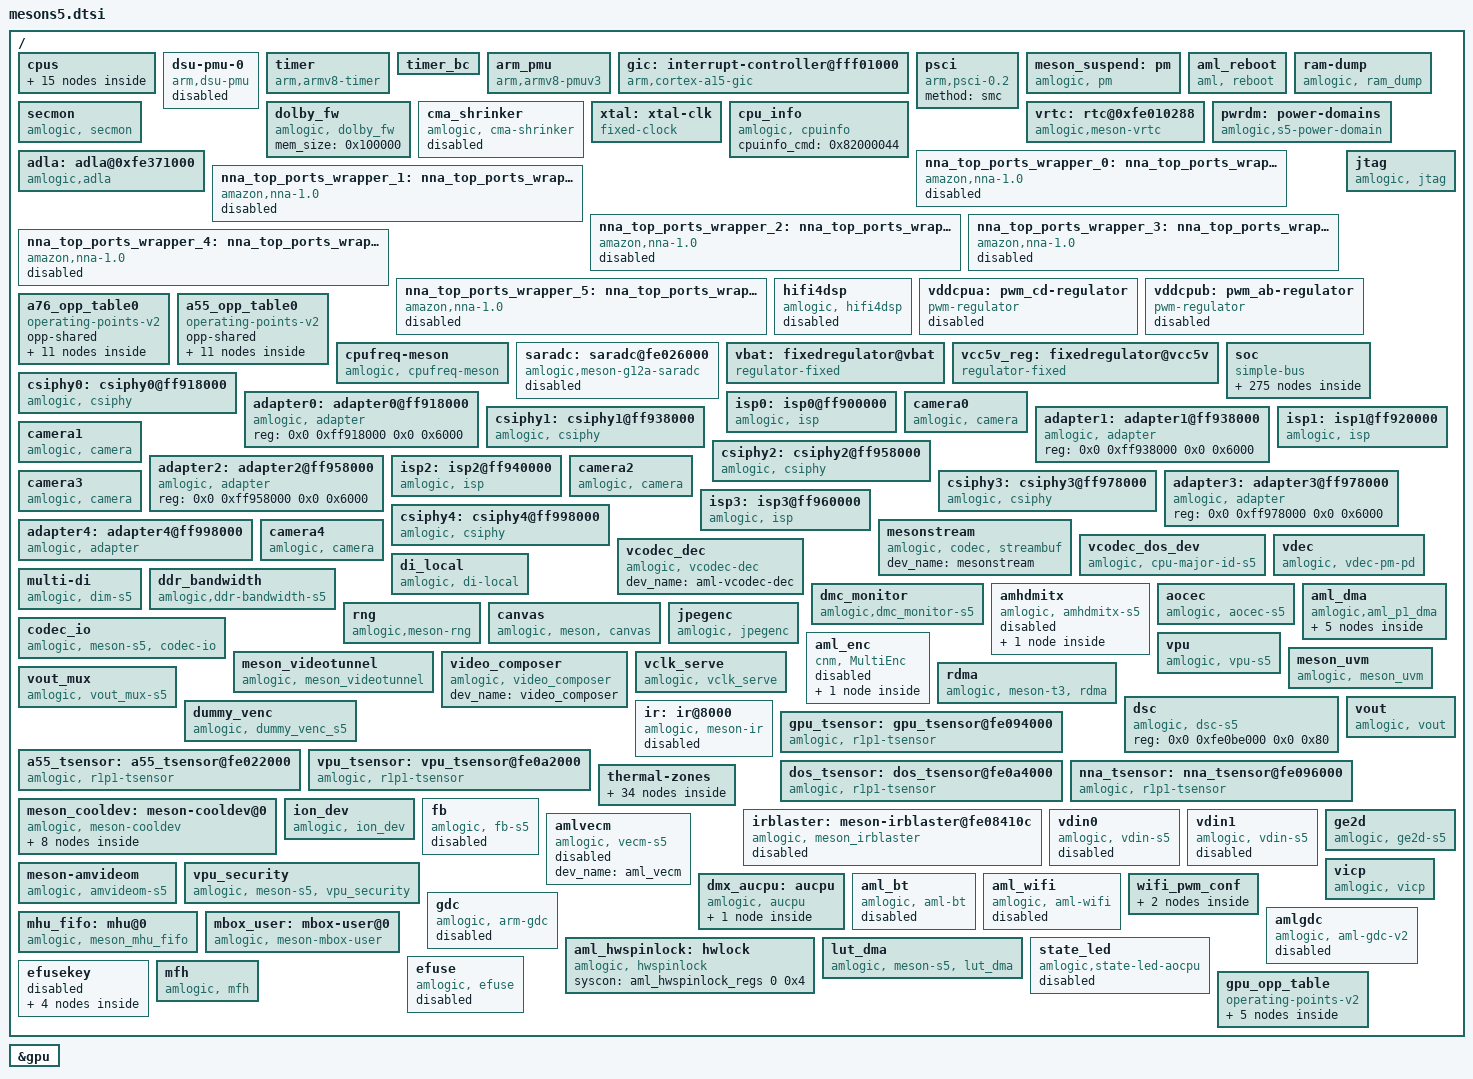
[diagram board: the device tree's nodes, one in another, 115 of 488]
// SPDX-License-Identifier: (GPL-2.0+ OR MIT)
/*
 * Copyright (c) 2019 Amlogic, Inc. All rights reserved.
 */

#include <dt-bindings/clock/s5-clkc.h>
#include <dt-bindings/interrupt-controller/irq.h>
#include <dt-bindings/interrupt-controller/arm-gic.h>
#include <dt-bindings/power/s5-pd.h>
#include <dt-bindings/clock/amlogic,s5-audio-clk.h>
#include <dt-bindings/gpio/gpio.h>
#include <dt-bindings/gpio/meson-s5-gpio.h>
#include <dt-bindings/reset/amlogic,meson-s5-reset.h>
#include <dt-bindings/pwm/pwm.h>
#include <dt-bindings/pwm/meson.h>
#include <dt-bindings/input/input.h>
#include <dt-bindings/input/meson_ir.h>
#include <dt-bindings/mailbox/amlogic,mbox.h>
#include "meson-ir-map.dtsi"
#include "meson-valhall.dtsi"
#include <dt-bindings/memory/meson-p1-sid-map.h>
#include <dt-bindings/hwspinlock/amlogic,hwspinlock.h>
/ {
	cpus:cpus {
		#address-cells = <2>;
		#size-cells = <0>;

		cpu-map {
			cluster0:cluster0 {
				core0 {
					cpu = <&CPU0>;
				};
				core1 {
					cpu = <&CPU1>;
				};
				core2 {
					cpu = <&CPU2>;
				};
				core3 {
					cpu = <&CPU3>;
				};
				core4 {
					cpu = <&CPU4>;
				};
			};
		};

		CPU0:cpu@0 {
			device_type = "cpu";
			compatible = "arm,cortex-a55","arm,armv8";
			reg = <0x0 0x0>;
			enable-method = "psci";
			cpu-idle-states = <&CPU_SLEEP_0 &SYSTEM_SLEEP_0>;
			#cooling-cells = <2>;
			clocks = <&clkc CLKID_CPU_CLK>,
				<&clkc CLKID_CPU_DYN_CLK>,
				<&clkc CLKID_SYS_PLL>,
				<&clkc CLKID_DSU_CLK>,
				<&clkc CLKID_DSU_DYN_CLK>,
				<&clkc CLKID_GP1_PLL>;
			clock-names = "core_clk",
				"low_freq_clk_parent",
				"high_freq_clk_parent",
				"dsu_clk",
				"dsu_pre_parent",
				"dsu_pre_parent2";
			operating-points-v2 = <&a55_opp_table0>;
			voltage-tolerance = <0>;
			clock-latency = <50000>;
			capacity-dmips-mhz = <512>;
			dynamic-power-coefficient = <1024>;
			cpu-supply = <&vddcpua>;
			cpu_supply_external_used;
			dsu-opp-table = <1200000 879000 1500000 939000>;
			dsu_clock_shared;
			dsu-low-rate = <1000000>;
			dvfs_sibling_core_num = <4>;
			dvfs_sibling_cores = <0 1 2 3>;
		};

		CPU1:cpu@1 {
			device_type = "cpu";
			compatible = "arm,cortex-a55","arm,armv8";
			reg = <0x0 0x1>;
			enable-method = "psci";
		    cpu-idle-states = <&CPU_SLEEP_0 &SYSTEM_SLEEP_0>;
			#cooling-cells = <2>;
			clocks = <&clkc CLKID_CPU_CLK>,
				<&clkc CLKID_CPU_DYN_CLK>,
				<&clkc CLKID_SYS_PLL>,
				<&clkc CLKID_DSU_CLK>,
				<&clkc CLKID_DSU_DYN_CLK>,
				<&clkc CLKID_GP1_PLL>;
			clock-names = "core_clk",
				"low_freq_clk_parent",
				"high_freq_clk_parent",
				"dsu_clk",
				"dsu_pre_parent",
				"dsu_pre_parent2";
			operating-points-v2 = <&a55_opp_table0>;
			voltage-tolerance = <0>;
			clock-latency = <50000>;
			capacity-dmips-mhz = <512>;
			dynamic-power-coefficient = <1024>;
			cpu-supply = <&vddcpua>;
			cpu_supply_external_used;
			dsu-opp-table = <1200000 879000 1500000 939000>;
			dsu_clock_shared;
			dsu-low-rate = <1000000>;
			dvfs_sibling_core_num = <4>;
			dvfs_sibling_cores = <0 1 2 3>;
		};

		CPU2:cpu@2 {
			device_type = "cpu";
			compatible = "arm,cortex-a55","arm,armv8";
			reg = <0x0 0x2>;
			enable-method = "psci";
			cpu-idle-states = <&CPU_SLEEP_0 &SYSTEM_SLEEP_0>;
			#cooling-cells = <2>;
			clocks = <&clkc CLKID_CPU_CLK>,
				<&clkc CLKID_CPU_DYN_CLK>,
				<&clkc CLKID_SYS_PLL>,
				<&clkc CLKID_DSU_CLK>,
				<&clkc CLKID_DSU_DYN_CLK>,
				<&clkc CLKID_GP1_PLL>;
			clock-names = "core_clk",
				"low_freq_clk_parent",
				"high_freq_clk_parent",
				"dsu_clk",
				"dsu_pre_parent",
				"dsu_pre_parent2";
			operating-points-v2 = <&a55_opp_table0>;
			voltage-tolerance = <0>;
			clock-latency = <50000>;
			capacity-dmips-mhz = <512>;
			dynamic-power-coefficient = <1024>;
			cpu-supply = <&vddcpua>;
			cpu_supply_external_used;
			dsu-opp-table = <1200000 879000 1500000 939000>;
			dsu_clock_shared;
			dsu-low-rate = <1000000>;
			dvfs_sibling_core_num = <4>;
			dvfs_sibling_cores = <0 1 2 3>;
		};

		CPU3:cpu@3 {
			device_type = "cpu";
			compatible = "arm,cortex-a55","arm,armv8";
			reg = <0x0 0x3>;
			enable-method = "psci";
			cpu-idle-states = <&CPU_SLEEP_0 &SYSTEM_SLEEP_0>;
			#cooling-cells = <2>;
			clocks = <&clkc CLKID_CPU_CLK>,
				<&clkc CLKID_CPU_DYN_CLK>,
				<&clkc CLKID_SYS_PLL>,
				<&clkc CLKID_DSU_CLK>,
				<&clkc CLKID_DSU_DYN_CLK>,
				<&clkc CLKID_GP1_PLL>;
			clock-names = "core_clk",
				"low_freq_clk_parent",
				"high_freq_clk_parent",
				"dsu_clk",
				"dsu_pre_parent",
				"dsu_pre_parent2";
			operating-points-v2 = <&a55_opp_table0>;
			voltage-tolerance = <0>;
			clock-latency = <50000>;
			capacity-dmips-mhz = <512>;
			dynamic-power-coefficient = <1024>;
			cpu-supply = <&vddcpua>;
			cpu_supply_external_used;
			dsu-opp-table = <1200000 879000 1500000 939000>;
			dsu_clock_shared;
			dsu-low-rate = <1000000>;
			dvfs_sibling_core_num = <4>;
			dvfs_sibling_cores = <0 1 2 3>;
		};

		CPU4:cpu@4 {
			device_type = "cpu";
			compatible = "arm,cortex-a76","arm,armv8";
			reg = <0x0 0x4>;
			enable-method = "psci";
			cpu-idle-states = <&CPU_SLEEP_0 &SYSTEM_SLEEP_0>;
			#cooling-cells = <2>;
			clocks = <&clkc CLKID_A76_CLK>,
				<&clkc CLKID_A76_DYN_CLK>,
				<&clkc CLKID_SYS1_PLL>,
				<&clkc CLKID_DSU_CLK>,
				<&clkc CLKID_DSU_DYN_CLK>,
				<&clkc CLKID_GP1_PLL>;
			clock-names = "core_clk",
				"low_freq_clk_parent",
				"high_freq_clk_parent",
				"dsu_clk",
				"dsu_pre_parent",
				"dsu_pre_parent2";
			operating-points-v2 = <&a76_opp_table0>;
			voltage-tolerance = <0>;
			cpu-supply = <&vddcpub>;
			dsu-supply = <&vddcpua>;
			clock-latency = <50000>;
			capacity-dmips-mhz = <1024>;
			dynamic-power-coefficient = <512>;
			dsu-opp-table = <1200000 879000 1500000 939000>;
			dsu_clock_shared;
			dsu-low-rate = <1000000>;
			dvfs_sibling_core_num = <1>;
			dvfs_sibling_cores = <4>;
		};

		idle-states {
			entry-method = "arm,psci-0.2";
			CPU_SLEEP_0: cpu-sleep-0 {
					compatible = "arm,idle-state";
					arm,psci-suspend-param = <0x0010000>;
					local-timer-stop;
					entry-latency-us = <4000>;
					exit-latency-us = <5000>;
					min-residency-us = <10000>;
			};
			SYSTEM_SLEEP_0: system-sleep-0 {
					compatible = "arm,idle-state";
					arm,psci-suspend-param = <0x0000000>;
					entry-latency-us = <0x3fffffff>;
					exit-latency-us = <0x40000000>;
					min-residency-us = <0xffffffff>;
			};
		};
	};

	dsu-pmu-0 {
		compatible = "arm,dsu-pmu";
		status = "disabled";
		cpus = <&CPU0>,<&CPU1>,<&CPU2>,<&CPU3>,<&CPU4>;
		interrupts = <GIC_SPI 230 IRQ_TYPE_LEVEL_HIGH>;
	};

	timer {
		compatible = "arm,armv8-timer";
		interrupts = <GIC_PPI 13 0xff08>,
				<GIC_PPI 14 0xff08>,
				<GIC_PPI 11 0xff08>,
				<GIC_PPI 10 0xff08>;
	};

	timer_bc {
		/*compatible = "amlogic,bc-timer";*/
		reg= <0x0 0xfe0100D8 0x0 0x4 0x0 0xfe0100DC 0x0 0x4>;
		timer_name = "Meson TimerD";
		clockevent-rating=<300>;
		clockevent-shift=<20>;
		clockevent-features=<0x23>;
		interrupts = <0 3 1>;
		bit_enable=<7>;
		bit_mode=<6>;
		bit_resolution=<0>;
		resolution_1us=<1>;
		min_delta_ns=<10>;
	};

	arm_pmu {
		compatible = "arm,armv8-pmuv3";
		private-interrupts;
		interrupts = <GIC_SPI 231 IRQ_TYPE_LEVEL_HIGH>,
			     <GIC_SPI 232 IRQ_TYPE_LEVEL_HIGH>,
			     <GIC_SPI 233 IRQ_TYPE_LEVEL_HIGH>,
			     <GIC_SPI 234 IRQ_TYPE_LEVEL_HIGH>,

			     <GIC_SPI 235 IRQ_TYPE_LEVEL_HIGH>,
			     <GIC_SPI 236 IRQ_TYPE_LEVEL_HIGH>,
			     <GIC_SPI 237 IRQ_TYPE_LEVEL_HIGH>,
			     <GIC_SPI 238 IRQ_TYPE_LEVEL_HIGH>;
	};

	gic: interrupt-controller@fff01000 {
		compatible = "arm,cortex-a15-gic", "arm,cortex-a9-gic";
		#interrupt-cells = <3>;
		#address-cells = <0>;
		interrupt-controller;
		reg = <0x0 0xfff01000 0 0x1000>,
		      <0x0 0xfff02000 0 0x0100>;
		interrupts = <GIC_PPI 9 0xf04>;
	};

	psci {
		compatible = "arm,psci-0.2";
		method = "smc";
	};

	meson_suspend:pm {
		compatible = "amlogic, pm";
		status = "okay";
		device_name = "aml_pm";
		extend_resume_reason;
		reg = <0x0 0xfe010288 0x0 0x4>, /*SYSCTRL_STATUS_REG2*/
			<0x0 0xfe0102dc 0x0 0x4>; /*SYSCTRL_STICKY_REG7*/
	};

	aml_reboot {
		compatible = "aml, reboot";
		sys_reset = <0x84000009>;
		sys_poweroff = <0x84000008>;
		dis_nb_cpus_in_shutdown;
		extend_reboot_reason; /* Support up to 128 reboot reasons*/
		reg = <0x0 0xfe01037c 0x0 0x4>; /* SEC_AO_SEC_SD_CFG15 */
		status = "okay";
	};

	ram-dump {
		compatible = "amlogic, ram_dump";
		status = "okay";
		reg = <0x0 0xFE0102D8 0x0 4>;
		reg-names = "SYSCTRL_STICKY_REG6";
		store_device = "data";
	};

	dolby_fw: dolby_fw {
		compatible = "amlogic, dolby_fw";
		mem_size = <0x100000>;
		status = "okay";
	};

	secmon {
		compatible = "amlogic, secmon";
		memory-region = <&secmon_reserved>;
		in_base_func = <0x82000020>;
		out_base_func = <0x82000021>;
		reserve_mem_size = <0x00400000>;
		clear_range = <0x05100000 0x200000>;
	};

	cma_shrinker: cma_shrinker {
		compatible = "amlogic, cma-shrinker";
		status = "disabled";
		adj  = <0 100 200 250 900 950>;
		free = <8192 12288 16384 24576 28672 32768>;
	};

	xtal: xtal-clk {
		compatible = "fixed-clock";
		clock-frequency = <24000000>;
		clock-output-names = "xtal";
		#clock-cells = <0>;
	};

	cpu_info {
		compatible = "amlogic, cpuinfo";
		status = "okay";
		cpuinfo_cmd = <0x82000044>;
	};

	vrtc: rtc@0xfe010288 {
		compatible = "amlogic,meson-vrtc";
		reg = <0x0 0xfe010288 0x0 0x4>;
		status = "okay";
		mboxes = <&mhu_fifo S5_REE2AO>;
	};

	pwrdm: power-domains {
		compatible = "amlogic,s5-power-domain";
		#power-domain-cells = <1>;
		status = "okay";
	};

	adla: adla@0xfe371000 {
		compatible = "amlogic,adla";
		dev_name = "adla";
		status = "okay";
		reg = <0x0 0xfe371000 0x0 0x2000
			0x0 0xf7038000 0x0 0x40000
			>;
		reg-names = "adla_reg\0adla_sram";
		interrupt-names = "adla";
		interrupts = <0 148 1>;
		clocks = <&clkc CLKID_NNA>;
		clock-names = "adla_core_clk";
		assigned-clocks =<&clkc CLKID_NNA>;
		assigned-clock-parentsd = <&clkc CLKID_FCLK_DIV2P5>;
		assigned-clock-rates = <800000000>;
		power-domains=<&pwrdm PDID_S5_NNA_4T>;
		//memory-region = <&nna_cma_reserved>;
		smmu;
		regulator_nn = "pwm_regulator";
	};

	nna_top_ports_wrapper_0: nna_top_ports_wrapper@fe370000 {
		compatible = "amazon,nna-1.0";
		device-name = "acenna0";
		status = "disabled";
//		clocks = <&clkc  CLKID_NNA0>;
//		assigned-clocks =<&clkc CLKID_NNA0>;
//		assigned-clock-parentsd = <&clkc CLKID_FCLK_DIV2P5>;
//		assigned-clock-rates = <800000000>;
//		clock-names = "nna_clk_gate";
		interrupt-names = "nna_interrupt";
		interrupts = <0 148 1>;
		minor-number = <0>;
		//power-domains = <&pwrdm PDID_P1_NNA_A>,
		//		<&pwrdm PDID_P1_NNA_TOP>;
		//power-domain-names = "pwrc-core","pwrc-top";
		reg = <0x0 0xfe370000 0x0 0x1000>;
		reg-names = "nna_irq_wrapper";
	};

	nna_top_ports_wrapper_1: nna_top_ports_wrapper@fe371000 {
		compatible = "amazon,nna-1.0";
		device-name = "acenna1";
		status = "disabled";
//		clocks = <&clkc  CLKID_NNA1>;
//		assigned-clocks =<&clkc CLKID_NNA1>;
//		assigned-clock-parentsd = <&clkc CLKID_FCLK_DIV2P5>;
//		assigned-clock-rates = <800000000>;
//		clock-names = "nna_clk_gate";
		interrupt-names = "nna_interrupt";
		interrupts = <0 149 1>;
		minor-number = <1>;
		//power-domains = <&pwrdm PDID_P1_NNA_B>,
		//		<&pwrdm PDID_P1_NNA_TOP>;
		//power-domain-names = "pwrc-core","pwrc-top";
		reg = <0x0 0xfe371000 0x0 0x1000>;
		reg-names = "nna_irq_wrapper";
	};

	nna_top_ports_wrapper_2: nna_top_ports_wrapper@fe372000 {
		compatible = "amazon,nna-1.0";
		device-name = "acenna2";
		status = "disabled";
//		clocks = <&clkc  CLKID_NNA2>;
//		assigned-clocks =<&clkc CLKID_NNA2>;
//		assigned-clock-parentsd = <&clkc CLKID_FCLK_DIV2P5>;
//		assigned-clock-rates = <800000000>;
//		clock-names = "nna_clk_gate";
		interrupt-names = "nna_interrupt";
		interrupts = <0 150 1>;
		minor-number = <2>;
		//power-domains = <&pwrdm PDID_P1_NNA_C>,
		//		<&pwrdm PDID_P1_NNA_TOP>;
		//power-domain-names = "pwrc-core","pwrc-top";
		reg = <0x0 0xfe372000 0x0 0x1000>;
		reg-names = "nna_irq_wrapper";
	};

	nna_top_ports_wrapper_3: nna_top_ports_wrapper@fe373000 {
		compatible = "amazon,nna-1.0";
		device-name = "acenna3";
		status = "disabled";
//		clocks = <&clkc  CLKID_NNA3>;
//		assigned-clocks =<&clkc CLKID_NNA3>;
//		assigned-clock-parentsd = <&clkc CLKID_FCLK_DIV2P5>;
//		assigned-clock-rates = <800000000>;
//		clock-names = "nna_clk_gate";
		interrupt-names = "nna_interrupt";
		interrupts = <0 151 1>;
		minor-number = <3>;
		//power-domains = <&pwrdm PDID_P1_NNA_D>,
		//		<&pwrdm PDID_P1_NNA_TOP>;
		//power-domain-names = "pwrc-core","pwrc-top";
		reg = <0x0 0xfe373000 0x0 0x1000>;
		reg-names = "nna_irq_wrapper";
	};
	nna_top_ports_wrapper_4: nna_top_ports_wrapper@fe374000 {
		compatible = "amazon,nna-1.0";
		device-name = "acenna4";
		status = "disabled";
//		clocks = <&clkc  CLKID_NNA4>;
//		assigned-clocks =<&clkc CLKID_NNA4>;
//		assigned-clock-parentsd = <&clkc CLKID_FCLK_DIV2P5>;
//		assigned-clock-rates = <800000000>;
//		clock-names = "nna_clk_gate";
		interrupt-names = "nna_interrupt";
		interrupts = <0 152 1>;
		minor-number = <4>;
		//power-domains = <&pwrdm PDID_P1_NNA_E>,
		//		<&pwrdm PDID_P1_NNA_TOP>;
		//power-domain-names = "pwrc-core","pwrc-top";
		reg = <0x0 0xfe374000 0x0 0x1000>;
		reg-names = "nna_irq_wrapper";
	};
	nna_top_ports_wrapper_5: nna_top_ports_wrapper@fe375000 {
		compatible = "amazon,nna-1.0";
		device-name = "acenna5";
		status = "disabled";
//		clocks = <&clkc  CLKID_NNA5>;
//		assigned-clocks =<&clkc CLKID_NNA5>;
//		assigned-clock-parentsd = <&clkc CLKID_FCLK_DIV2P5>;
//		assigned-clock-rates = <800000000>;
//		clock-names = "nna_clk_gate";
		interrupt-names = "nna_interrupt";
		interrupts = <0 153 1>;
		minor-number = <5>;
		//power-domains = <&pwrdm PDID_P1_NNA_F>,
		//		<&pwrdm PDID_P1_NNA_TOP>;
		//power-domain-names = "pwrc-core","pwrc-top";
		reg = <0x0 0xfe375000 0x0 0x1000>;
		reg-names = "nna_irq_wrapper";
	};

	jtag {
		compatible = "amlogic, jtag";
		status = "okay";
		select = "disable"; /* disable/jtag_a/jtag_b */
		pinctrl-names= "jtag_a_pins", "jtag_b_pins";
		pinctrl-0= <&jtag_a_pins>;
		pinctrl-1= <&jtag_b_pins>;
	};

	hifi4dsp: hifi4dsp {
		compatible = "amlogic, hifi4dsp";
		memory-region = <&dsp_fw_reserved>;
		reg = <0 0xfe340018 0 0x114>,   /*dspa base address*/
			  <0 0xfe350018 0 0x114>,   /*dspb base address*/
			  <0 0xfe010258 0 0x4>,     /*dspa status counter*/
			  <0 0xfe01025c 0 0x4>,     /*dspb status counter*/
			  <0 0x30820000 0 0x80000>; /*dsp shm region*/
		dsp-monitor-period-ms = <1000>;
		reg-names = "dspa_top_reg", "dspb_top_reg";
//		clocks = <&clkc CLKID_DSPA>, <&clkc CLKID_DSPB>;
//		clock-names = "dspa_clk", "dspb_clk";
		dsp-start-mode = <1>; /*0:scpi start mode,1:smc start mode*/
		dsp-cnt = <2>;
		dspaoffset = <0x00000>;
		dspboffset = <0x800000>;
		bootlocation = <1>;   /*1: boot from DDR, 2: from sram, 3...*/
		boot_sram_addr = <0xfff00000>;
		boot_sram_size = <0x80000>;
		//dspsrambase = <0xf7100000>;
		//dspsramsize = <0x100000>;
		//power-domains = <&pwrdm PDID_P1_DSPA>,
		//				<&pwrdm PDID_P1_DSPB>;
		//power-domain-names = "dspa", "dspb";
		status = "disabled";
	};

	vddcpua: pwm_cd-regulator {
		compatible = "pwm-regulator";
		pwms = <&pwm_cd MESON_PWM_1 1500 0>;
		regulator-name = "vddcpua";
		regulator-min-microvolt = <689000>;
		regulator-max-microvolt = <1049000>;
		regulator-always-on;
		max-duty-cycle = <1500>;
		/* Voltage Duty-Cycle */
		voltage-table = <1049000 0>,
				<1039000 3>,
				<1029000 6>,
				<1019000 9>,
				<1009000 12>,
				<999000 14>,
				<989000 17>,
				<979000 20>,
				<969000 23>,
				<959000 26>,
				<949000 29>,
				<939000 31>,
				<929000 34>,
				<919000 37>,
				<909000 40>,
				<899000 43>,
				<889000 45>,
				<879000 48>,
				<869000 51>,
				<859000 54>,
				<849000 56>,
				<839000 59>,
				<829000 62>,
				<819000 65>,
				<809000 68>,
				<799000 70>,
				<789000 73>,
				<779000 76>,
				<769000 79>,
				<759000 81>,
				<749000 84>,
				<739000 87>,
				<729000 89>,
				<719000 92>,
				<709000 95>,
				<699000 98>,
				<689000 100>;
		status = "disabled";
	};

	vddcpub: pwm_ab-regulator {
		compatible = "pwm-regulator";
		pwms = <&pwm_ab MESON_PWM_0 1500 0>;
		regulator-name = "vddcpub";
		regulator-min-microvolt = <689000>;
		regulator-max-microvolt = <1049000>;
		regulator-always-on;
		max-duty-cycle = <1500>;
		/* Voltage Duty-Cycle */
		voltage-table = <1049000 0>,
				<1039000 3>,
				<1029000 6>,
				<1019000 9>,
				<1009000 12>,
				<999000 14>,
				<989000 17>,
				<979000 20>,
				<969000 23>,
				<959000 26>,
				<949000 29>,
				<939000 31>,
				<929000 34>,
				<919000 37>,
				<909000 40>,
				<899000 43>,
				<889000 45>,
				<879000 48>,
				<869000 51>,
				<859000 54>,
				<849000 56>,
				<839000 59>,
				<829000 62>,
				<819000 65>,
				<809000 68>,
				<799000 70>,
				<789000 73>,
				<779000 76>,
				<769000 79>,
				<759000 81>,
				<749000 84>,
				<739000 87>,
				<729000 89>,
				<719000 92>,
				<709000 95>,
				<699000 98>,
				<689000 100>;
		status = "disabled";
	};

	a76_opp_table0: a76_opp_table0 {
		compatible = "operating-points-v2";
		opp-shared;

		opp00 {
			opp-hz = /bits/ 64 <500000000>;
			opp-microvolt = <839000>;
		};
		opp01 {
			opp-hz = /bits/ 64 <666000000>;
			opp-microvolt = <839000>;
		};
		opp02 {
			opp-hz = /bits/ 64 <1000000000>;
			opp-microvolt = <849000>;
		};
		opp03 {
			opp-hz = /bits/ 64 <1200000000>;
			opp-microvolt = <869000>;
		};
		opp04 {
			opp-hz = /bits/ 64 <1392000000>;
			opp-microvolt = <889000>;
		};
		opp05 {
			opp-hz = /bits/ 64 <1512000000>;
			opp-microvolt = <909000>;
		};
		opp06 {
			opp-hz = /bits/ 64 <1608000000>;
			opp-microvolt = <929000>;
		};
		opp07 {
			opp-hz = /bits/ 64 <1704000000>;
			opp-microvolt = <949000>;
		};
		opp08 {
			opp-hz = /bits/ 64 <1800000000>;
			opp-microvolt = <969000>;
		};
		opp09 {
			opp-hz = /bits/ 64 <1896000000>;
			opp-microvolt = <989000>;
		};
		opp10 {
			opp-hz = /bits/ 64 <2016000000>;
			opp-microvolt = <1009000>;
		};
	};

	a55_opp_table0: a55_opp_table0 {
		compatible = "operating-points-v2";
		opp-shared;

		opp00 {
			opp-hz = /bits/ 64 <500000000>;
			opp-microvolt = <839000>;
		};
		opp01 {
			opp-hz = /bits/ 64 <666000000>;
			opp-microvolt = <839000>;
		};
		opp02 {
			opp-hz = /bits/ 64 <1000000000>;
			opp-microvolt = <869000>;
		};
		opp03 {
			opp-hz = /bits/ 64 <1200000000>;
			opp-microvolt = <879000>;
		};
		opp04 {
			opp-hz = /bits/ 64 <1392000000>;
			opp-microvolt = <919000>;
		};
		opp05 {
			opp-hz = /bits/ 64 <1512000000>;
			opp-microvolt = <939000>;
		};
		opp06 {
			opp-hz = /bits/ 64 <1608000000>;
			opp-microvolt = <959000>;
		};
		opp07 {
			opp-hz = /bits/ 64 <1704000000>;
			opp-microvolt = <979000>;
		};
		opp08 {
			opp-hz = /bits/ 64 <1800000000>;
			opp-microvolt = <989000>;
		};
		opp09 {
			opp-hz = /bits/ 64 <1896000000>;
			opp-microvolt = <999000>;
		};
		opp10 {
			opp-hz = /bits/ 64 <2016000000>;
			opp-microvolt = <1009000>;
		};
	};

	cpufreq-meson {
		compatible = "amlogic, cpufreq-meson";
		status = "okay";
	};

	saradc: saradc@fe026000 {
		compatible = "amlogic,meson-g12a-saradc",
			   "amlogic,meson-saradc";
		status = "disabled";
		#io-channel-cells = <1>;
		clocks = <&xtal>,
			<&clkc CLKID_SYS_CLK_SAR_ADC>,
			<&clkc CLKID_SARADC>,
			<&clkc CLKID_SARADC_SEL>;
		clock-names = "clkin", "core",
			"adc_clk", "adc_sel";
		interrupts = <GIC_SPI 181 IRQ_TYPE_EDGE_RISING>;
		reg = <0x00 0xfe026000 0x00 0x48>;
	};

	vbat: fixedregulator@vbat {
		compatible = "regulator-fixed";
		regulator-name = "12V";
		regulator-min-microvolt = <12000000>;
		regulator-max-microvolt = <12000000>;
		regulator-boot-on;
		regulator-always-on;
	};

	vcc5v_reg: fixedregulator@vcc5v {
		vin-supply = <&vbat>;
		compatible = "regulator-fixed";
		regulator-name = "VCC5V";
		regulator-min-microvolt = <5000000>;
		regulator-max-microvolt = <5000000>;
		pinctrl-names = "default";
		// GPIOC_7 is OD mode
		//gpio = <&gpio GPIOC_7 GPIO_ACTIVE_HIGH>;
		startup-delay-us = <70000>;
		enable-active-high;
		regulator-boot-on;
		regulator-always-on;
	};

	soc {
		compatible = "simple-bus";
		#address-cells = <2>;
		#size-cells = <2>;
		ranges;

		apb4: apb4@fe000000 {
			compatible = "simple-bus";
			reg = <0x0 0xfe000000 0x0 0x480000>;
			#address-cells = <2>;
			#size-cells = <2>;
			ranges = <0x0 0x0 0x0 0xfe000000 0x0 0x480000>;
			status = "okay";

			clkc: clock-controller {
				compatible = "amlogic,s5-clkc";
				#clock-cells = <1>;
				reg = <0x0 0x0 0x0 0xb54>,
				      <0x0 0x8000 0x0 0x34c>,
				      <0x0 0xe040 0x0 0xbc>;
				reg-names = "basic", "pll", "cpu_clk";
				clocks = <&xtal>;
				clock-names = "xtal";
				status = "okay";
			};

			meson_clk_msr@48000 {
				compatible = "amlogic,meson-s5-clk-measure";
				reg = <0x0 0x48000 0x0 0x1c>;
				status = "okay";
			};

			watchdog@2100 {
				compatible = "amlogic,meson-sc2-wdt";
				status = "okay";
				/* 0:userspace, 1:kernel */
				amlogic,feed_watchdog_mode = <1>;
				reg = <0x0 0x2100 0x0 0x10>;
				clocks = <&xtal>;
			};

			periphs_pinctrl: pinctrl@4008 {
				compatible = "amlogic,meson-s5-periphs-pinctrl";
				#address-cells = <2>;
				#size-cells = <2>;
				ranges;

				gpio: bank@4008 {
					reg = <0x0 0x4000 0x0 0x008c>,
					      <0x0 0x4200 0x0 0x026c>;
					reg-names = "mux", "gpio";
					gpio-controller;
					#gpio-cells = <2>;
					gpio-ranges = <&periphs_pinctrl 0 0 107>;
				};
			};

			storage_pinctrl: pinctrl@86000 {
				compatible = "amlogic,meson-s5-storage-pinctrl";
				#address-cells = <2>;
				#size-cells = <2>;
				ranges;

				gpio_sto: bank@86000 {
					reg = <0x0 0x86000 0x0 0x8>,
					      <0x0 0x86380 0x0 0x020>;
					reg-names = "mux", "gpio";
					gpio-controller;
					#gpio-cells = <2>;
					gpio-ranges = <&storage_pinctrl 0 0 13>;
				};
			};

			gpio_intc: interrupt-controller@40c0 {
				compatible = "amlogic,meson-s5-gpio-intc",
					     "amlogic,meson-gpio-intc";
				reg = <0x0 0x40c0 0x0 0x50>;
				interrupt-controller;
				#interrupt-cells = <2>;
				amlogic,channel-interrupts =
					<288 289 290 291 292 293 294 295 296 297 298 299
					 300 301 302 303 304 305 306 307 308 309 310 311
					 312 313 314 315 316 317 318 319>;
			};

			spicc0: spi@50000 {
				compatible = "amlogic,meson-s5-spicc";
				reg = <0x0 0x50000 0x0 0x44>;
				interrupts = <GIC_SPI 183 IRQ_TYPE_EDGE_RISING>;
				clocks = <&clkc CLKID_SYS_CLK_SPICC0>,
					 <&clkc CLKID_SPICC0>;
				clock-names = "core", "async";
				#address-cells = <1>;
				#size-cells = <0>;
				//power-domains = <&pwrdm PDID_T7_SPICC0>;
				status = "disabled";
			};

			spicc1: spi@52000 {
				compatible = "amlogic,meson-s5-spicc";
				reg = <0x0 0x52000 0x0 0x44>;
				interrupts = <GIC_SPI 184 IRQ_TYPE_EDGE_RISING>;
				clocks = <&clkc CLKID_SYS_CLK_SPICC1>,
					 <&clkc CLKID_SPICC1>;
				clock-names = "core", "async";
				#address-cells = <1>;
				#size-cells = <0>;
				//power-domains = <&pwrdm PDID_T7_SPICC1>;
				status = "disabled";
			};

			spicc2: spi@54000 {
				compatible = "amlogic,meson-s5-spicc";
				reg = <0x0 0x54000 0x0 0x44>;
				interrupts = <GIC_SPI 167 IRQ_TYPE_EDGE_RISING>;
				clocks = <&clkc CLKID_SYS_CLK_SPICC2>,
					 <&clkc CLKID_SPICC2>;
				clock-names = "core", "async";
				#address-cells = <1>;
				#size-cells = <0>;
				//power-domains = <&pwrdm PDID_T7_SPICC2>;
				status = "disabled";
			};

			spifc: spi@56000 {
				compatible = "amlogic,meson-spifc";
				status = "disabled";
				reg = <0x0 0x56000 0x0 0x80>;
//				clock-names = "default";
//				clocks = <&clkc CLKID_SYS_CLK_SPIFC>;
				pinctrl-names = "default";
				pinctrl-0 = <&spifc_all_pins>;
				#address-cells = <1>;
				#size-cells = <0>;
				spi-nor@0 {
					compatible = "jedec,spi-nor";
					status = "disabled";
					reg = <0>;
					spi-max-frequency = <16000000>;
				};
			};

			pwm_ab: pwm@58000 {
				compatible = "amlogic,meson-v2-pwm";
				reg = <0x0 0x58000 0x0 0x24>;
				#pwm-cells = <3>;
				clocks = <&clkc CLKID_PWM_A>,
						<&clkc CLKID_PWM_B>;
				clock-names = "clkin0", "clkin1";
				status = "disabled";
			};

			pwm_cd: pwm@5a000 {
				compatible = "amlogic,meson-v2-pwm";
				reg = <0x0 0x5a000 0x0 0x24>;
				#pwm-cells = <3>;
				clocks = <&clkc CLKID_PWM_C>,
						<&clkc CLKID_PWM_D>;
				clock-names = "clkin0", "clkin1";
				status = "disabled";
			};

			pwm_ef: pwm@5c000 {
				compatible = "amlogic,meson-v2-pwm";
				reg = <0x0 0x5c000 0x0 0x24>;
				#pwm-cells = <3>;
				clocks = <&clkc CLKID_PWM_E>,
						<&clkc CLKID_PWM_F>;
				clock-names = "clkin0", "clkin1";
				status = "disabled";
			};

			pwm_gh: pwm@5e000 {
				compatible = "amlogic,meson-v2-pwm";
				reg = <0x0 0x5e000 0x0 0x24>;
				#pwm-cells = <3>;
				clocks = <&clkc CLKID_PWM_G>,
						<&clkc CLKID_PWM_H>;
				clock-names = "clkin0", "clkin1";
				status = "disabled";
			};

			pwm_ij: pwm@60000 {
				compatible = "amlogic,meson-v2-pwm";
				reg = <0x0 0x60000 0x0 0x24>;
				#pwm-cells = <3>;
				clocks = <&clkc CLKID_PWM_I>,
						<&clkc CLKID_PWM_J>;
				clock-names = "clkin0", "clkin1";
				status = "disabled";
			};

			i2c0: i2c@66000 {
				compatible = "amlogic,meson-i2c";
				reg = <0x0 0x66000 0x0 0x48>;
				interrupts = <GIC_SPI 160 IRQ_TYPE_EDGE_RISING>;
				#address-cells = <1>;
				#size-cells = <0>;
				clocks = <&clkc CLKID_SYS_CLK_I2C_M_A>;
				status = "disabled";
			};
			i2c1: i2c@68000 {
				compatible = "amlogic,meson-i2c";
				reg = <0x0 0x68000 0x0 0x48>;
				interrupts = <GIC_SPI 161 IRQ_TYPE_EDGE_RISING>;
				#address-cells = <1>;
				#size-cells = <0>;
				clocks = <&clkc CLKID_SYS_CLK_I2C_M_B>;
				status = "disabled";
			};
			i2c2: i2c@6a000 {
				compatible = "amlogic,meson-i2c";
				reg = <0x0 0x6a000 0x0 0x48>;
				interrupts = <GIC_SPI 162 IRQ_TYPE_EDGE_RISING>;
				#address-cells = <1>;
				#size-cells = <0>;
				clocks = <&clkc CLKID_SYS_CLK_I2C_M_C>;
				status = "disabled";
			};
			i2c3: i2c@6c000 {
				compatible = "amlogic,meson-i2c";
				reg = <0x0 0x6c000 0x0 0x48>;
				interrupts = <GIC_SPI 163 IRQ_TYPE_EDGE_RISING>;
				#address-cells = <1>;
				#size-cells = <0>;
				clocks = <&clkc CLKID_SYS_CLK_I2C_M_D>;
				status = "disabled";
			};
			i2c4: i2c@6e000 {
				compatible = "amlogic,meson-i2c";
				reg = <0x0 0x6e000 0x0 0x48>;
				interrupts = <GIC_SPI 164 IRQ_TYPE_EDGE_RISING>;
				#address-cells = <1>;
				#size-cells = <0>;
				clocks = <&clkc CLKID_SYS_CLK_I2C_M_E>;
				status = "disabled";
			};
			i2c5: i2c@70000 {
				compatible = "amlogic,meson-i2c";
				reg = <0x0 0x070000 0x0 0x48>;
				interrupts = <GIC_SPI 165 IRQ_TYPE_EDGE_RISING>;
				#address-cells = <1>;
				#size-cells = <0>;
				clocks = <&clkc CLKID_SYS_CLK_I2C_M_F>;
				status = "disabled";
			};
			uart_B: serial@7a000 {
				compatible = "amlogic,meson-uart";
				reg = <0x0 0x7a000 0x0 0x18>;
				interrupts = <0 169 1>;
				status = "disabled";
				clocks = <&xtal
					&clkc CLKID_SYS_CLK_UART_B>;
				clock-names = "clk_uart",
						"clk_gate";
				xtal_tick_en = <2>;
				fifosize = < 64 >;
				pinctrl-names = "default";
				pinctrl-0 = <&b_uart_pins>;
			};

			reset: reset-controller@2000 {
				compatible = "amlogic,meson-p1-reset";
				reg = <0x0 0x2000 0x0 0xa0>;
				#reset-cells = <1>;
			};

			cpu_version {
				compatible = "amlogic,meson-gx-ao-secure", "syscon";
				status = "disable";
				reg=<0x0 0x10220 0x0 0x140>;
			};

			gbl_timer_core: global-timer@8e000 {
				compatible = "amlogic,meson-glb-timer-core";
				reg = <0x0 0x8e000 0x0 0x28>;
				reg-names = "topctrl";
//				clocks = <&clkc CLKID_SYS_CLK_GLB>;
//				clock-names = "glb_clk";
				//hwlocks = <&aml_hwlock HWSPINLOCK_ID_GLB_TIMER>;
			};

			gbl_timer_isp: global-timer@8e040 {
				compatible = "amlogic,meson-glb-timer-isp";
				reg = <0x0 0x8e040 0x0 0x140>;
				reg-names = "isp";
			};

			gbl_timer_gpio_input: global-timer@8e180 {
				compatible = "amlogic,meson-glb-timer-gpio-input";
				reg-names = "input-src-sel";
				reg = <0x0 0x8e180 0x0 0x56c>;
			};

			aml_hwspinlock_regs: syscon@e300 {
				compatible = "syscon";
				reg = <0x0 0xe300 0x0 0x80>;
			};
		};

		crg21_otg: crg21otg@fe038000 {
			compatible = "amlogic, amlogic-crg-otg";
			status = "disabled";
			usb2-phy-reg = <0xfe03808c>;
			usb2-phy-reg-size = <0x80>;
			m31-phy-reg = <0xfe074000>;
			m31-phy-reg-size = <0x80>;
			usb3-phy-reg = <0xfe038080>;
			usb3-phy-reg-size = <0x20>;
			interrupts = <0 128 IRQ_TYPE_EDGE_RISING>;
			udc-name = "fdd00000.crgudc2";
		};

		crg20: crg@fdf00000 {
			compatible = "amlogic, crg";
			status = "disabled";
			reg = <0x0 0xfdf00000 0x0 0x100000>;
			interrupts = <0 129 4>;
			usb-phy = <&crg_phy_20>, <&crg3_phy_20>;
			cpu-type = "gxl";
			clock-src = "usb3.0";
			clocks = <&clkc CLKID_SYS_CLK_USB>;
			clock-names = "crg_general";
		};

		crg30_drd: crg2drd@fdd00000 {
			status = "disabled";
			reg = <0x0 0xfdd00000 0x0 0x100000>;
			interrupts = <0 131 4>;
			usb-phy = <&usb2_m31_0_phy>, <&usb3_m31_0_phy>;
			cpu-type = "gxl";
			clock-src = "usb3.0";
			clocks = <&clkc CLKID_SYS_CLK_USB>;
			clock-names = "crg_general";
		};

		crg31: crg@fde00000 {
			compatible = "amlogic, crg";
			status = "disabled";
			reg = <0x0 0xfde00000 0x0 0x100000>;
			interrupts = <0 130 4>;
			usb-phy = <&usb2_m31_1_phy>, <&usb3_m31_1_phy>;
			cpu-type = "gxl";
			clock-src = "usb3.0";
			clocks = <&clkc CLKID_SYS_CLK_USB>;
			clock-names = "crg_general";
		};

		usb2_m31_0_phy: usb2m310phy {
			compatible = "amlogic, amlogic-usb2-m31-phy";
			status = "disable";
			#phy-cells = <0>;
		};

		usb3_m31_0_phy: usb3m310phy {
			compatible = "amlogic, amlogic-usb3-m31-phy";
			status = "disable";
			#phy-cells = <0>;
			reg = <0x0 0xfe002000 0x0 0x100>;
			reset-level = <0x40>;
			phy-reg = <0xfe074000>;
			phy-reg-size = <0x2000>;
			m31phy-reset-level-bit = <10>;
			m31ctl-reset-level-bit = <6>;
			m31-utmi-reset-level-bit = <2>;
			u3-combx0-reset-bit = <53>;
			uncomposite = <1>;
		};

		usb2_m31_1_phy: usb2m311phy {
			compatible = "amlogic, amlogic-usb2-m31-phy";
			status = "disable";
			#phy-cells = <0>;
		};

		usb3_m31_1_phy: usb3m311phy {
			compatible = "amlogic, amlogic-usb3-m31-phy";
			status = "disable";
			#phy-cells = <0>;
			reg = <0x0 0xfe002000 0x0 0x100>;
			reset-level = <0x40>;
			phy-reg = <0xfe076000>;
			phy-reg-size = <0x2000>;
			m31phy-reset-level-bit = <9>;
			m31ctl-reset-level-bit = <5>;
			uncomposite = <1>;
		};

		crg_phy_20: crgphy20@fe072000 {
			compatible = "amlogic, amlogic-crg-drd-usb2";
			status = "disable";
			#phy-cells = <0>;
			reg = <0x0 0xfe03c000 0x0 0x80
				0x0 0xFE002000 0x0 0x100
				0x0 0xfe072000 0x0 0x2000>;
			pll-setting-1 = <0x09400414>;
			pll-setting-2 = <0x927E0000>;
			pll-setting-3 = <0xac5f69e5>;
			pll-setting-4 = <0xbe18>;
			pll-setting-5 = <0x7>;
			pll-setting-6 = <0x78000>;
			pll-setting-7 = <0xe0004>;
			pll-setting-8 = <0xe000c>;
			dis-thred-enhance = <0x2>;/**t7-0x38:bit[26-27]**/
			version = <3>;
			//power-domains = <&pwrdm PDID_SC2_USB_COMB>;
			phy0-reset-level-bit = <8>;
			usb-reset-bit = <3>;
			reset-level = <0x40>;
			pwr-ctl = <0>;
			clocks = <&clkc CLKID_SYS_CLK_USB>;
			clock-names = "crg_general";
			phy-id = <0>;
			usb-phy-trim-reg = <0xfe010330>;
		};

		crg3_phy_20: crg3phy20@fe03c080 {
			compatible = "amlogic, amlogic-crg-drd-usb3";
			status = "disable";
			#phy-cells = <0>;
			reg = <0x0 0xfe03c080 0x0 0x20>;
			phy1-reg = <0xfe072000>;
			phy1-reg-size = <0x2000>;
			reset-reg = <0xFE002000>;
			reset-reg-size = <0x100>;
			reset-level = <0x40>;
			phy-id = <0>;
		};

		crg_udc_2: crgudc2@0xfdd00000 {
			compatible = "amlogic, crg_udc";
			status = "disable";
			device_name = "crg_udc_2";
			reg = <0x0 0xfdd00000 0x0 0x100000>;
			interrupts = <0 131 4>;
			clock-src = "usb0"; /** clock src */
			port-speed = <3>; /** 0: default, high, 1: full */
			phy-reg = <0xfe074000>;
			phy-reg-size = <0x1000>;
			clocks = <&clkc CLKID_SYS_CLK_USB>;
			clock-names = "usb_general";
			phy-id = <2>;
			controller-type = <4>;
		};

		dummy_codec:dummy{
			#sound-dai-cells = <0>;
			compatible = "amlogic, aml_dummy_codec";
			status = "okay";
		};
		amlogic_codec:t9015{
			#sound-dai-cells = <0>;
			compatible = "amlogic, s4_codec_T9015";
			reg = <0x0 0xFE01A000 0x0 0x2000>;
			tocodec_inout = <2>;
			tdmout_index = <2>;
			ch0_sel = <0>;
			ch1_sel = <1>;

			reset-names = "acodec";
			resets = <&reset RESET_ACODEC>;

			status = "okay";
		};

		audio_data: audio_data {
			compatible = "amlogic, audio_data";
			mem_in_base_cmd = <0x82000020>;
			query_licence_cmd = <0x82000050>;
			status = "okay";
		};

		amaudio: amaudio {
			compatible = "amlogic, amaudio";
			reg = <0x0 0xfe440000 0x0 0x10000>;
			reg-names = "otp_tee_base";
			status = "okay";
		};

		audiobus: audiobus@0xFE330000 {
			compatible = "amlogic, audio-controller", "simple-bus";
			reg = <0x0 0xFE330000 0x0 0x3000>;
			#address-cells = <2>;
			#size-cells = <2>;
			ranges = <0x0 0x0 0x0 0xFE330000 0x0 0x3000>;
			chip_id = <0x3e>;
		//	power-domains = <&pwrdm PDID_T7_AUDIO>;
			status = "okay";

			clkaudio: audio_clocks {
				compatible = "amlogic, s5-audio-clocks";
				#clock-cells = <1>;
				reg = <0x0 0x0 0x0 0xb0>;
				status = "okay";
			};
			ddr_manager {
				compatible =
					"amlogic, s5-audio-ddr-manager";
				interrupts = <
					GIC_SPI 32 IRQ_TYPE_EDGE_RISING
					GIC_SPI 33 IRQ_TYPE_EDGE_RISING
					GIC_SPI 34 IRQ_TYPE_EDGE_RISING
					GIC_SPI 45 IRQ_TYPE_EDGE_RISING
					GIC_SPI 36 IRQ_TYPE_EDGE_RISING
					GIC_SPI 37 IRQ_TYPE_EDGE_RISING
					GIC_SPI 38 IRQ_TYPE_EDGE_RISING
					GIC_SPI 46 IRQ_TYPE_EDGE_RISING
				>;
				interrupt-names =
					"toddr_a", "toddr_b", "toddr_c",
					"toddr_d",
					"frddr_a", "frddr_b", "frddr_c",
					"frddr_d";
				status = "okay";
			};
			pcpd_monitor_a: pcpd_monitor@0 {
				compatible = "amlogic, pcpda_monitor";
				interrupts = <GIC_SPI 84
					IRQ_TYPE_EDGE_RISING>;
				interrupt-names = "irq_pcpd";
				status = "disabled";
			};
			pcpd_monitor_b: pcpd_monitor@1 {
				compatible = "amlogic, pcpdb_monitor";
				interrupts = <GIC_SPI 85
					IRQ_TYPE_EDGE_RISING>;
				interrupt-names = "irq_pcpd";
				status = "disabled";
			};

		pinctrl_audio: pinctrl {
				compatible = "amlogic, audio-pinctrl";
				status = "okay";
			};
		};/* end of audiobus*/

		/* eARC */
		audio_earc: bus@fe333000 {
			compatible = "simple-bus";
			reg = <0x0 0xfe333000 0x0 0x1000>;
			#address-cells = <2>;
			#size-cells = <2>;
			ranges = <0x0 0x0 0x0 0xfe333000 0x0 0x1000>;

			earc: earc@0 {
				compatible = "amlogic, s5-snd-earc";
				#sound-dai-cells = <0>;

				status = "disabled";

				reg =
					<0x0 0x800 0x0 0x400>,
					<0x0 0xc00 0x0 0x200>,
					<0x0 0xe00 0x0 0x200>;
				reg-names =
					"rx_cmdc",
					"rx_dmac",
					"rx_top";

				clocks = < &clkaudio CLKID_EARCRX_CMDC
					&clkaudio CLKID_EARCRX_DMAC
					&clkc CLKID_FCLK_DIV4
					&clkc CLKID_FCLK_DIV4
					&clkaudio CLKID_EARCTX_CMDC
					&clkaudio CLKID_EARCTX_DMAC
					&clkc CLKID_FCLK_DIV4
					&clkc CLKID_HIFI_PLL
					>;
				clock-names =
					"rx_cmdc",
					"rx_dmac",
					"rx_cmdc_srcpll",
					"rx_dmac_srcpll";

				interrupts = <GIC_SPI 48 IRQ_TYPE_LEVEL_HIGH>;
				interrupt-names = "earc_rx";
			};
		};

		/* Sound iomap */
		aml_snd_iomap {
			compatible = "amlogic, snd-iomap";
			status = "okay";
			#address-cells=<2>;
			#size-cells=<2>;
			ranges;
			pdm_bus {
				reg = <0x0 0xFE331000 0x0 0x400>;
			};
			audiobus_base {
				reg = <0x0 0xFE330000 0x0 0x1000>;
			};
			audiolocker_base {
				reg = <0x0 0xFE331400 0x0 0x400>;
			};
			eqdrc_base {
				reg = <0x0 0xFE332000 0x0 0x1000>;
			};
			vad_base {
				reg = <0x0 0xFE331800 0x0 0x400>;
			};
			resampleA_base {
				reg = <0x0 0xFE331c00 0x0 0x104>;
			};
			resampleB_base {
				reg = <0x0 0xFE334000 0x0 0x104>;
			};
			pdm_bus_b {
				reg = <0x0 0xFE334800 0x0 0x400>;
			};
		};

		pcie1: pcie@e0000000 {
			compatible = "amlogic, amlogic-pcie-v3";
			reg = <0x0 0xe0000000 0x0 0x1000
				0x0 0xfe02c000 0x0 0x2000
				0x0 0xe0000000 0x0 0x8000000
				0x0 0xe7e00000 0x0 0x200000
				0x0 0xfe076000 0x0 0x2000
				0x0 0xfe002040 0x0 0x10>;
			reg-names = "apb-base", "pcictrl-base", "axi-base",
				    "ecam-base", "phy-base", "reset-base";
			interrupts = <GIC_SPI 412 IRQ_TYPE_EDGE_RISING
				     GIC_SPI 408 IRQ_TYPE_EDGE_RISING
				     GIC_SPI 409 IRQ_TYPE_EDGE_RISING
				     GIC_SPI 410 IRQ_TYPE_EDGE_RISING
				     GIC_SPI 411 IRQ_TYPE_EDGE_RISING>;
			#interrupt-cells = <1>;
			msi-controller;
			msi-parent = <&pcie1>;
			interrupt-parent = <&gic>;
			bus-range = <0x0 0xff>;
			#address-cells = <3>;
			#size-cells = <2>;
			interrupt-map-mask = <0 0 0 7>;
			interrupt-map = <0 0 0 1 &gic GIC_SPI 408
					IRQ_TYPE_EDGE_RISING>,
					<0 0 0 2 &gic GIC_SPI 409
					IRQ_TYPE_EDGE_RISING>,
					<0 0 0 3 &gic GIC_SPI 410
					IRQ_TYPE_EDGE_RISING>,
					<0 0 0 4 &gic GIC_SPI 411
					IRQ_TYPE_EDGE_RISING>;
			device_type = "pci";
			ranges =
				/*
				 * <0x81000000 0 0xe0001000
				 * 0 0xe0001000 0x0 0x100000>,
				 */
				/*downstream I/O */
				<0x82000000 0 0xe1000000 0x0 0xe1000000
				0 0x4000000>;
				/* non-prefetched memory */
			num-lanes = <1>;
			port-num = <1>;
			phy-type = <1>;
			pinctrl-names = "default";
			pinctrl-0 = <&pcieck_1_pins>;

			clocks = <&clkc CLKID_PCIE1_PLL
				&clkc CLKID_SYS_CLK_PCIE
				&clkc CLKID_SYS_CLK_PCIE_PHY1
				&clkc CLKID_PCIE1_HCSL_OUT
				&clkc CLKID_PCIE_400M
				&clkc CLKID_PCIE_TL_CLK
				&clkc CLKID_PCIE_CLK>;
			clock-names = "pcie_refpll",
					"pcie",
					"pcie_phy",
					"pcie_hcsl",
					"pcie_400m_clk",
					"pcie_tl_clk",
					"cts_pcie_clk";
			/*reset-gpio-type
			 *0:Shared pad(no reset)
			 *1:OD pad2:Normal pad
			 */
			gpio-type = <2>;
			pcie-gen2-l0-rst-bit = <12>;
			pcie-apb-rst-bit = <6>;
			pcie-phy-rst-bit = <9>;
			pcie-a-rst-bit = <13>;
			pcie-rst-bit = <4>;
			pcie-rst-mask = <0xff>;
			power-domains = <&pwrdm PDID_S5_PCIE1>;
			status = "disabled";
			/* iommu-map = <0x100 &smmu P1_SID_PCIE 0x10>; */
			dma-ranges = <0x0 0x0 0x0 0x0 0x0 0x0 0xe0000000>;
		};

		pcie0: pcie@e8000000 {
			compatible = "amlogic, amlogic-pcie-v3";
			reg = <0x0 0xe8000000 0x0 0x1000
				0x0 0xfe02a000 0x0 0x2000
				0x0 0xe8000000 0x0 0x8000000
				0x0 0xefe00000 0x0 0x200000
				0x0 0xfe074000 0x0 0x2000
				0x0 0xfe002040 0x0 0x10>;
			reg-names = "apb-base", "pcictrl-base", "axi-base",
				    "ecam-base", "phy-base", "reset-base";
			interrupts = <GIC_SPI 78 IRQ_TYPE_EDGE_RISING
				      GIC_SPI 188 IRQ_TYPE_EDGE_RISING
				      GIC_SPI 91 IRQ_TYPE_EDGE_RISING
				      GIC_SPI 92 IRQ_TYPE_EDGE_RISING
				      GIC_SPI 93 IRQ_TYPE_EDGE_RISING>;
			#interrupt-cells = <1>;
			msi-controller;
			msi-parent = <&pcie0>;
			interrupt-parent = <&gic>;
			bus-range = <0x0 0xff>;
			#address-cells = <3>;
			#size-cells = <2>;
			interrupt-map-mask = <0 0 0 7>;
			interrupt-map = <0 0 0 1 &gic GIC_SPI 188
					IRQ_TYPE_EDGE_RISING>,
					<0 0 0 2 &gic GIC_SPI 91
					IRQ_TYPE_EDGE_RISING>,
					<0 0 0 3 &gic GIC_SPI 92
					IRQ_TYPE_EDGE_RISING>,
					<0 0 0 4 &gic GIC_SPI 93
					IRQ_TYPE_EDGE_RISING>;
			device_type = "pci";
			ranges =
				/*
				 *  <0x81000000 0 0xff000000
				 *  0 0xe8001000 0x0 0x100000
				 */
				/*downstream I/O */
				<0x82000000 0 0xe8200000 0x0 0xe8200000
				0 0x7c00000>;
				/* non-prefetched memory */
			num-lanes = <1>;
			port-num = <0>;
			phy-type = <1>;
			pinctrl-names = "default";
			pinctrl-0 = <&pcieck_0_pins>;

			clocks = <&clkc CLKID_PCIE_PLL
				&clkc CLKID_SYS_CLK_PCIE
				&clkc CLKID_SYS_CLK_PCIE_PHY0
				&clkc CLKID_PCIE_HCSL_OUT
				&clkc CLKID_PCIE_400M
				&clkc CLKID_PCIE_TL_CLK
				&clkc CLKID_PCIE_CLK>;
			clock-names = "pcie_refpll",
					"pcie",
					"pcie_phy",
					"pcie_hcsl",
					"pcie_400m_clk",
					"pcie_tl_clk",
					"cts_pcie_clk";
			/*reset-gpio-type
			 *0:Shared pad(no reset)
			 *1:OD pad2:Normal pad
			 */
			gpio-type = <2>;
			pcie-gen2-l0-rst-bit = <18>;
			pcie-apb-rst-bit = <7>;
			pcie-phy-rst-bit = <10>;
			pcie-a-rst-bit = <14>;
			pcie-rst-bit = <12>;
			pcie-rst-mask = <0xff>;
			power-domains = <&pwrdm PDID_S5_PCIE0>;
			status = "disabled";
			/* iommu-map = <0x100 &smmu P1_SID_PCIE 0x10>; */
			dma-ranges = <0x0 0x0 0x0 0x0 0x0 0x0 0xe0000000>;
		};

		sd_emmc_c: mmc@fe08c000 {
			compatible = "amlogic,meson-axg-mmc";
			reg = <0x0 0xfe08c000 0x0 0x800>,
				<0x0 0xfe000168 0x0 0x4>,
				<0x0 0xfe086000 0x0 0x4>;
			interrupts = <GIC_SPI 178 IRQ_TYPE_EDGE_RISING>;
			status = "disabled";
			clocks = <&clkc CLKID_SYS_CLK_SD_EMMC_C>,
				<&clkc CLKID_SD_EMMC_C_CLK_SEL>,
				 <&clkc CLKID_SD_EMMC_C_CLK>,
				 <&xtal>,
				 <&clkc CLKID_GP0_PLL>,
				 <&clkc CLKID_GP0_PLL>;
			clock-names = "core", "mux0", "mux1",
					"clkin0", "clkin1", "clkin2";
			card_type = <1>;
			src_clk_rate = <1536000000>;
			mmc_debug_flag;
			ignore_desc_busy;
			tx_delay = <20>;
			nwr_cnt = <12>;
		//	supports-cqe;
		//	resets = <&reset RESET_SD_EMMC_C>;
		};

		sd_emmc_b: sd@fe08a000 {
			compatible = "amlogic,meson-axg-mmc";
			reg = <0x0 0xfe08a000 0x0 0x800>,
				<0x0 0xfe00016c 0x0 0x4>,
				<0x0 0xfe00400c 0x0 0x4>;
			interrupts = <GIC_SPI 239 IRQ_TYPE_EDGE_RISING>;
			status = "disabled";
			clocks = <&clkc CLKID_SYS_CLK_SD_EMMC_B>,
				<&clkc CLKID_SD_EMMC_B_CLK_SEL>,
				 <&clkc CLKID_SD_EMMC_B_CLK>,
				 <&xtal>,
				 <&clkc CLKID_FCLK_DIV2>;
			clock-names = "core", "mux0", "mux1",
					"clkin0", "clkin1";
			card_type = <5>;
			ignore_desc_busy;
			use_intf3_tuning;
			sdr_core_phase = <1>;
			mmc_debug_flag;
			//resets = <&reset RESET_SD_EMMC_B>;
		};

		sd_emmc_a: sdio@fe088000 {
			compatible = "amlogic,meson-axg-mmc";
			reg = <0x0 0xfe088000 0x0 0x800>,
				<0x0 0xfe00016c 0x0 0x4>,
				<0x0 0xfe004038 0x0 0x4>;
			interrupts = <GIC_SPI 177 IRQ_TYPE_LEVEL_HIGH>;
			status = "disabled";
			clocks = <&clkc CLKID_SYS_CLK_SD_EMMC_A>,
				<&clkc CLKID_SD_EMMC_A_CLK_SEL>,
				 <&clkc CLKID_SD_EMMC_A_CLK>,
				 <&xtal>,
				 <&clkc CLKID_FCLK_DIV2>;
			clock-names = "core", "mux0", "mux1",
					"clkin0", "clkin1";
			card_type = <3>;
			cap-sdio-irq;
			keep-power-in-suspend;
			use_intf3_tuning;
			mmc_debug_flag;
			//resets = <&reset RESET_SD_EMMC_A>;
		};

		ethmac: ethernet@fdc00000 {
			compatible = "amlogic,meson-axg-dwmac",
				     "snps,dwmac-3.70a",
				     "snps,dwmac";
			reg = <0x0 0xfdc00000 0x0 0x10000>,
			      <0x0 0xfe024000 0x0 0x8>;
			interrupts = <GIC_SPI 74 IRQ_TYPE_LEVEL_HIGH>;
			interrupt-names = "macirq";
			power-domains = <&pwrdm PDID_S5_ETH>;
			clocks = <&clkc CLKID_SYS_CLK_ETH>,
				 <&clkc CLKID_FCLK_DIV2>,
				 <&clkc CLKID_FCLK_CLK50M>;
			clock-names = "stmmaceth", "clkin0", "clkin1";
			rx-fifo-depth = <4096>;
			tx-fifo-depth = <2048>;
			/*1:inphy; 2:exphy;*/
			internal_phy = <2>;
			cali_val = <0x80000>;
			status = "disabled";
			ext_mdio: mdio {
				#address-cells = <1>;
				#size-cells = <0>;
				compatible = "snps,dwmac-mdio";
				external_phy: ethernet-phy@0 {
					reg = <0>;
					max-speed = <1000>;
					reset-assert-us = <20000>;
					reset-deassert-us = <50000>;
					reset-gpios = <&gpio GPIOZ_15 (GPIO_ACTIVE_LOW |
								GPIO_OPEN_DRAIN)>;
				};
			};
		};

		uart_A: serial@fe078000 {
			compatible = "amlogic,meson-uart";
			reg = <0x0 0xfe078000 0x0 0x18>;
			interrupts = <0 168 1>;
			status = "disabled";
			clocks = <&xtal
				&clkc CLKID_SYS_CLK_UART_A>;
			clock-names = "clk_uart",
					"clk_gate";
			xtal_tick_en = <2>;
			fifosize = < 64 >;
			pinctrl-names = "default";
		};

		uart_C: serial@fe07c000 {
			compatible = "amlogic,meson-uart";
			reg = <0x0 0xfe07c000 0x0 0x18>;
			interrupts = <0 170 1>;
			status = "disabled";
			clocks = <&xtal
				&clkc CLKID_SYS_CLK_UART_C>;
			clock-names = "clk_uart",
					"clk_gate";
			fifosize = < 64 >;
			pinctrl-names = "default";
			pinctrl-0 = <&c_uart_pins1>;
		};

		uart_D: serial@fe07e000 {
			compatible = "amlogic,meson-uart";
			status = "disabled";
			reg = <0x0 0xfe07e000 0x0 0x18>;
			interrupts = <0 171 1>;
			clocks = <&xtal
				&clkc CLKID_SYS_CLK_UART_D>;
			clock-names = "clk_uart",
					"clk_gate";
			fifosize = < 64 >;
			pinctrl-names = "default";
			pinctrl-0 = <&d_uart_pins>;
		};

		uart_E: serial@fe080000 {
			compatible = "amlogic,meson-uart";
			status = "disabled";
			reg = <0x0 0xfe080000 0x0 0x18>;
			interrupts = <0 172 1>;
			clocks = <&xtal
				&clkc CLKID_SYS_CLK_UART_E>;
			clock-names = "clk_uart",
					"clk_gate";
			fifosize = < 64 >;
			pinctrl-names = "default";
			pinctrl-0 = <&e_uart_pins>;
		};

		uart_F: serial@fe082000 {
			compatible = "amlogic,meson-uart";
			status = "disabled";
			reg = <0x0 0xfe082000 0x0 0x18>;
			interrupts = <0 180 1>;
			clocks = <&xtal
				&clkc CLKID_SYS_CLK_UART_F>;
			clock-names = "clk_uart",
					"clk_gate";
			fifosize = < 64 >;
			pinctrl-names = "default";
			pinctrl-0 = <&f_uart_pins>;
		};
	};

	csiphy0: csiphy0@ff918000 {
		compatible = "amlogic, csiphy";
		reg = <0x0 0xff918000 0x0 0x3000>,
				<0x0 0xff9a0000 0x0 0x400>;
		reg-names = "csi_phy","csi_aphy";
		//power-domains = <&pwrdm PDID_P1_MIPI_ISP_TOP>;
//		clocks = <&clkc CLKID_CSIPHY0>;
//		clock-names = "cts_mipi_csi_phy_clk";
	};

	adapter0: adapter0@ff918000 {
		compatible = "amlogic, adapter";
		reg = <0x0 0xff918000 0x0 0x6000>;
		reg-names = "adapter";
	};

	isp0: isp0@ff900000 {
		compatible = "amlogic, isp";
		reg = <0x0 0xff900000 0x0 0x10000>;
		/* interrupt-parent = <&intc>; */
		//power-domains = <&pwrdm PDID_P1_ISP_A>;
//		clocks = <&clkc CLKID_ISP0>;
//		clock-names = "cts_mipi_isp_clk";
		interrupts = <0 97 1>;
	};

	camera0 {
		status = "okay";
		compatible = "amlogic, camera";
		index = <0>;
		csiphy = <&csiphy0>;
		adapter = <&adapter0>;
		isp = <&isp0>;
	};

	csiphy1: csiphy1@ff938000 {
		compatible = "amlogic, csiphy";
		reg = <0x0 0xff938000 0x0 0x3000>,
				<0x0 0xff9a0000 0x0 0x400>;
		reg-names = "csi_phy","csi_aphy";
		//power-domains = <&pwrdm PDID_P1_MIPI_ISP_TOP>;
//		clocks = <&clkc CLKID_CSIPHY1>;
//		clock-names = "cts_mipi_csi_phy_clk";
	};

	adapter1: adapter1@ff938000 {
		compatible = "amlogic, adapter";
		reg = <0x0 0xff938000 0x0 0x6000>;
		reg-names = "adapter";
	};

	isp1: isp1@ff920000 {
		compatible = "amlogic, isp";
		reg = <0x0 0xff920000 0x0 0x10000>;
		/* interrupt-parent = <&intc>; */
		//power-domains = <&pwrdm PDID_P1_ISP_B>;
//		clocks = <&clkc CLKID_ISP1>;
//		clock-names = "cts_mipi_isp_clk";
		interrupts = <0 105 1>;
	};

	camera1 {
		status = "okay";
		compatible = "amlogic, camera";
		index = <1>;
		csiphy = <&csiphy1>;
		adapter = <&adapter1>;
		isp = <&isp1>;
	};

	csiphy2: csiphy2@ff958000 {
		compatible = "amlogic, csiphy";
		reg = <0x0 0xff958000 0x0 0x3000>,
				<0x0 0xff9a0000 0x0 0x400>;
		reg-names = "csi_phy","csi_aphy";
		//power-domains = <&pwrdm PDID_P1_MIPI_ISP_TOP>;
//		clocks = <&clkc CLKID_CSIPHY2>;
//		clock-names = "cts_mipi_csi_phy_clk";
	};

	adapter2: adapter2@ff958000 {
		compatible = "amlogic, adapter";
		reg = <0x0 0xff958000 0x0 0x6000>;
		reg-names = "adapter";
	};

	isp2: isp2@ff940000 {
		compatible = "amlogic, isp";
		reg = <0x0 0xff940000 0x0 0x10000>;
		/* interrupt-parent = <&intc>; */
		//power-domains = <&pwrdm PDID_P1_ISP_C>;
//		clocks = <&clkc CLKID_ISP2>;
//		clock-names = "cts_mipi_isp_clk";
		interrupts = <0 113 1>;
	};

	camera2 {
		status = "okay";
		compatible = "amlogic, camera";
		index = <2>;
		csiphy = <&csiphy2>;
		adapter = <&adapter2>;
		isp = <&isp2>;
	};

	csiphy3: csiphy3@ff978000 {
		compatible = "amlogic, csiphy";
		reg = <0x0 0xff978000 0x0 0x3000>,
				<0x0 0xff9a0000 0x0 0x400>;
		reg-names = "csi_phy","csi_aphy";
		//power-domains = <&pwrdm PDID_P1_MIPI_ISP_TOP>;
//		clocks = <&clkc CLKID_CSIPHY3>;
//		clock-names = "cts_mipi_csi_phy_clk";
	};

	adapter3: adapter3@ff978000 {
		compatible = "amlogic, adapter";
		reg = <0x0 0xff978000 0x0 0x6000>;
		reg-names = "adapter";
	};

	isp3: isp3@ff960000 {
		compatible = "amlogic, isp";
		reg = <0x0 0xff960000 0x0 0x10000>;
		/* interrupt-parent = <&intc>; */
		//power-domains = <&pwrdm PDID_P1_ISP_D>;
//		clocks = <&clkc CLKID_ISP3>;
//		clock-names = "cts_mipi_isp_clk";
		interrupts = <0 121 1>;
	};

	camera3 {
		status = "okay";
		compatible = "amlogic, camera";
		index = <3>;
		csiphy = <&csiphy3>;
		adapter = <&adapter3>;
		isp = <&isp3>;
	};

	csiphy4: csiphy4@ff998000 {
		compatible = "amlogic, csiphy";
		reg = <0x0 0xff998000 0x0 0x3000>,
				<0x0 0xff9a0000 0x0 0x400>;
		reg-names = "csi_phy","csi_aphy";
		//power-domains = <&pwrdm PDID_P1_MIPI_ISP_TOP>;
//		clocks = <&clkc CLKID_CSIPHY4>;
//		clock-names = "cts_mipi_csi_phy_clk";
	};

	adapter4: adapter4@ff998000 {
		compatible = "amlogic, adapter";
		reg = <0x0 0xff998000 0x0 0x6000>,
				<0x0 0xff980000 0x0 0x1000>;
		reg-names = "adapter","wrmif";
//		clocks = <&clkc CLKID_ISP4>;
//		clock-names = "cts_mipi_wrmif_clk";
		interrupts = <0 81 1>;
	};

	camera4 {
		status = "okay";
		compatible = "amlogic, camera";
		index = <4>;
		csiphy = <&csiphy4>;
		adapter = <&adapter4>;
	};

	mesonstream {
		compatible = "amlogic, codec, streambuf";
		dev_name = "mesonstream";
		status = "okay";
	};
	vcodec_dos_dev: vcodec_dos_dev {
		compatible = "amlogic, cpu-major-id-s5";
		dev_name = "vcodec_dos_dev";
		status = "okay";
		reg = <0x0 0xfe320000 0x0 0x10000>,
			<0x0 0xfe036000 0x0 0x2000>;
		reg-names = "dosbus",
			"dmcbus";
		clocks = <&clkc CLKID_SYS_CLK_DOS
		    &clkc CLKID_VDEC
		    &clkc CLKID_HCODEC
		    &clkc CLKID_HEVC>;
		clock-names = "vdec",
		    "clk_vdec_mux",
		    "clk_hcodec_mux",
		    "clk_hevc_mux";
		assigned-clock-parents = <&clkc CLKID_VDEC0>,
		    <&clkc CLKID_HEVC0>;
		assigned-clocks = <&clkc CLKID_VDEC>,
		    <&clkc CLKID_HEVC>;
	};

	vdec {
		compatible = "amlogic, vdec-pm-pd";
		dev_name = "vdec.0";
		status = "okay";
		interrupts = <0 3 1
			0 23 1
			0 32 1
			0 10 1
			0 17 1
			0 18 1
			0 16 1>;
		interrupt-names = "vsync",
			"demux",
			"parser",
			"mailbox_0",
			"mailbox_1",
			"mailbox_2",
			"assist_mbox_irq_ee";
		power-domains = <&pwrdm PDID_S5_DOS_VDEC>,
			<&pwrdm PDID_S5_DOS_HCODEC>,
			<&pwrdm PDID_S5_DOS_HEVC_TOP>,
			<&pwrdm PDID_S5_DOS_HEVC_CORE1>;
		power-domain-names = "pwrc-vdec",
			"pwrc-hcodec",
			"pwrc-hevc",
			"pwrc-hevcb";
	};

	vcodec_dec {
		compatible = "amlogic, vcodec-dec";
		dev_name = "aml-vcodec-dec";
		status = "okay";
	};

	di_local {
		compatible = "amlogic, di-local";
		status = "okay";
	};

	multi-di {
		compatible = "amlogic, dim-s5";
		status = "okay";
		/* 0:use reserved; 1:use cma; 2:use cma as reserved */
		flag_cma = <4>;	//<1>;
		//memory-region = <&di_reserved>;
		memory-region = <&di_cma_reserved>;
		interrupts = <0 122 1
				0 123 1
				0 278 1>;
		interrupt-names = "pre_irq", "post_irq", "aisr_irq";
		clocks = <&clkc CLKID_VPU_CLKB>,
			<&clkc CLKID_VPU>;
		clock-names = "vpu_clkb",
			"vpu_mux";
		clock-range = <334 667>;
		/* buffer-size = <3621952>;(yuv422 8bit) */
		buffer-size = <4074560>;/*yuv422 fullpack*/
		/* reserve-iomap = "true"; */
		/* if enable nr10bit, set nr10bit-support to 1 */
		post-wr-support = <1>;
		nr10bit-support = <1>;
		nrds-enable = <1>;
		pps-enable = <1>;
		dct = <0>;//decontour disable
		hf	= <2>; //enable aisr
		en_4k = <0>;
		alloc_sct = <0>;
		po_fmt = <0>;
		/***************************************************
		 * t3 support 4k ,same with t7 ,no canvas,
		 * post_nub---default is 11
		 *            (T7/T3/SC2/S4 new path)post 11*5222400 = 56M,local 7*4075520 = 28m
		 * flag_cma---0: use reserved; 1:use cma; 2:use cma as reserved 4:use codec mem
		 * en_4k :en_4k---0: not support 4K;  1: enable 4K
		 *                2: dynamic: vdin: 4k enable, other source 4k disable
		 *                8: when 4k,output with a resolution is below 1080p
		 * keep_dec_vf---0:not keep; 1: keep dec vf for p;
		 *               2: dynamic keep dec vf for p,other is disable
		 * po_fmt---1: NV21/8;  2: nv12/8;  3: AFBC 422/10BIT;
		 *          4: dynamic(4K AFBC,10/422);
		 *          6: dynamic(from decoder 4K source,out is AFBC,10/420),other is 422/10BIT
		 * bypass_mem---0:nr not bypass; 1: nr bypass; 2: when 4k input ,nr is bypass;
		 *              3: bypass nr for 4k,but not from vdin;
		 * alloc_sct---0:not support; bit 0: for 4k; bit 1: for 1080p
		 * hf---0:not enable; 1: enable
		 ***************************************************/
	};

	ddr_bandwidth {
		compatible = "amlogic,ddr-bandwidth-s5";
		status = "okay";
		reg = <0 0xfe036000 0 0x200
		       0 0xfe034000 0 0x200
		       0 0xfe032000 0 0x200
		       0 0xfe030000 0 0x200
		       0 0xfe0368a4 0 0x4>;
		interrupts = <0 332 IRQ_TYPE_EDGE_RISING
			      0 336 IRQ_TYPE_EDGE_RISING
			      0 340 IRQ_TYPE_EDGE_RISING
			      0 54 IRQ_TYPE_EDGE_RISING>;
		interrupt-names = "ddr_bandwidth";
	};

	dmc_monitor {
		compatible = "amlogic,dmc_monitor-s5";
		status = "okay";
		reg = <0 0xfe036000 0 0x200
		       0 0xfe034000 0 0x200
		       0 0xfe032000 0 0x200
		       0 0xfe030000 0 0x200>;
		reg_base = <0xfe036000>;
		interrupts = <0 333 IRQ_TYPE_EDGE_RISING
			      0 337 IRQ_TYPE_EDGE_RISING
			      0 341 IRQ_TYPE_EDGE_RISING
			      0 55 IRQ_TYPE_EDGE_RISING>;
	};

	amhdmitx: amhdmitx{
		compatible = "amlogic, amhdmitx-s5";
		dev_name = "amhdmitx";
		status = "disabled";
		//power-domains = <&pwrdm PDID_T7_VI_CLK2>;
		vend-data = <&vend_data>;
		pinctrl-names="hdmitx_hpd", "hdmitx_ddc";
		pinctrl-0=<&hdmitx_hpd>;
		pinctrl-1=<&hdmitx_ddc>;
		interrupts = <0 80 4
			0 115 1>;
		interrupt-names = "hdmitx_hpd", "vrr_vsync";
		enc_idx = <0>;
		tx_max_frl_rate = <5>; /* max FRL_10G4L */
		reg =	<0x0 0xff800000 0x0 0x40000>,
			<0x0 0xfe3a0000 0x0 0x10000>,
			<0x0 0xfe390000 0x0 0x10000>,
			<0x0 0xfe010000 0x0 0x2000>,
			<0x0 0xfe00c000 0x0 0x2000>,
			<0x0 0xfe008000 0x0 0x2000>,
			<0x0 0xfe002000 0x0 0x2000>,
			<0x0 0xfe000000 0x0 0x2000>,
			<0x0 0xfe004000 0x0 0x200>;
		reg-names = "vpu",
			    "hdmitxcor",
			    "hdmitxtop",
			    "sysctrl",
			    "pwrctrl",
			    "anactrl",
			    "resetctrl",
			    "clkctrl",
			    "padctrl";

		vend_data: vend_data{ /* Should modified by Customer */
			vendor_name = "Amlogic"; /* Max Chars: 8 */
			product_desc = "MBox Meson Ref"; /* Max Chars: 16 */
			/* standards.ieee.org/develop/regauth/oui/oui.txt */
			vendor_id = <0x000000>;
		};
	};

	aocec: aocec {
		compatible = "amlogic, aocec-s5";
		dev_name = "aocec";
		status = "okay";
		vendor_name = "Amlogic"; /* Max Chars: 8     */
		/* Refer to the following URL at:
		 * http://standards.ieee.org/develop/regauth/oui/oui.txt
		 */
		vendor_id = <0x000000>;
		product_desc = "S5"; /* Max Chars: 16    */
		cec_osd_string = "AML_MBOX"; /* Max Chars: 14    */
		cec_version = <5>;/*5:1.4;6:2.0*/
		port_num = <1>;
		output = <1>;
		cec_sel = <1>;/*1:use one ip, 2:use 2 ip*/
		ee_cec; /*use cec b*/
		arc_port_mask = <0x1>;
		interrupts = <GIC_SPI 69 IRQ_TYPE_EDGE_RISING>;/*0:snps*/
		interrupt-names = "hdmi_aocecb";
		pinctrl-names = "default","hdmitx_aocecb","cec_pin_sleep";
		pinctrl-0=<&cec_b>;
		pinctrl-1=<&cec_b>;
		pinctrl-2=<&cec_b>;
		clocks = <&clkc CLKID_CECB_32K_CLKOUT>;
		clock-names = "cecb_clk";
		reg = <0x0 0xfe028000 0x0 0x2000
		       0x0 0xfe010000 0x0 0x2000
		       0x0 0xfe000000 0x0 0x2000
		       0x0 0xfe004000 0x0 0x2000>;
		reg-names = "ao","periphs","clock","pad_reg";
	};

	aml_dma {
		compatible = "amlogic,aml_p1_dma";
		reg = <0x0 0xfe440400 0x0 0x48>;
		interrupts = <0 24 1>;
		status = "okay";

		aml_aes {
			compatible = "amlogic,aes_g12a_dma";
			dev_name = "aml_aes_dma";
			status = "okay";
			iv_swap = /bits/ 8 <0x0>;
		};

		aml_sha {
			compatible = "amlogic,sha_dma";
			dev_name = "aml_sha_dma";
			status = "okay";
		};

		aml_tdes {
			compatible = "amlogic,des_dma,tdes_dma";
			dev_name = "aml_tdes_dma";
			status = "okay";
		};

		aml_sm4 {
			compatible = "amlogic,sm4_dma";
			dev_name = "aml_sm4_dma";
			status = "okay";
			iv_swap = /bits/ 8 <0x0>;
		};

		crypto {
			compatible = "amlogic,crypto_s5";
			dev_name = "aml_crypto_dev";
			status = "okay";
			thread = /bits/ 8 <0x5>;
			interrupts = <0 29 1>;
		};
	};

	rng {
		compatible = "amlogic,meson-rng";
		status = "okay";
		#address-cells = <2>;
		#size-cells = <2>;
		reg = <0x0 0xfe440788 0x0 0x0c>;
		quality = /bits/ 16 <1000>;
		version = <2>;
	};

	canvas: canvas{
		compatible = "amlogic, meson, canvas";
		dev_name = "amlogic-canvas";
		status = "okay";
		reg = <0x0 0xfe036048 0x0 0x2000>;
	};

	codec_io: codec_io {
		compatible = "amlogic, meson-s5, codec-io";
		status = "okay";
		#address-cells=<2>;
		#size-cells=<2>;
		ranges;
		/* use cbus space for reset_ctrl*/
		reg =	<0x0 0xfe002000 0x0 0x2000>,
			<0x0 0x0 0x0 0x0>,
			<0x0 0x0 0x0 0x0>,
			<0x0 0x0 0x0 0x00>,
			<0x0 0xff800000 0x0 0x40000>,
			<0x0 0xfe036000 0x0 0x2000>,
			<0x0 0x0 0x0 0x0>;
		reg-names = "cbus",
			    "dosbus",
			    "hiubus",
			    "aobus",
			    "vcbus",
			    "dmcbus",
			    "efusebus";
	};

	jpegenc{
		compatible = "amlogic, jpegenc";
		dev_name = "jpegenc";
		status = "okay";

		clocks = <&clkc CLKID_SYS_CLK_DOS
//			&clkc CLKID_VAPB
			&clkc CLKID_HCODEC>;

		clock-names =
			"clk_dos",
//			"clk_apb_dos",
			"clk_jpeg_enc";

//		clocks = <&clkc CLKID_HCODEC_P0>;
//		clock-names = "hcodec_p0";
		power-domains = <&pwrdm PDID_S5_DOS_HCODEC>;
		interrupts = <0 16 1 0 17 1 0 18 1>;
		interrupt-names = "dos_mbox_slow_irq0", "dos_mbox_slow_irq1", "dos_mbox_slow_irq2";
		//reset-names = "jpegenc_rst";
		//resets = <&reset RESET_BRG_HCODEC_PIPL0>;
	};
	aml_enc {
		compatible = "cnm, MultiEnc";
		dev_name = "amvenc_multi";
		status = "disabled";
		config_mm_sz_mb = <200>;
//		clocks = <&clkc CLKID_DOS
//			&clkc CLKID_VAPB
//			&clkc CLKID_WAVE_A_GATE
//			&clkc CLKID_WAVE_B_GATE
//			&clkc CLKID_WAVE_C_GATE>;
//		clock-names =
//			"clk_dos",
//			"clk_apb_dos",
//			"clk_MultiEnc_A",
//			"clk_MultiEnc_B",
//			"clk_MultiEnc_C";
		interrupts = <0 94 1 0 95 1>;
		interrupt-names = "multienc_irq", "multienc_idle_irq";
		#address-cells=<2>;
		#size-cells=<2>;
		pwr-ctl = <0>;
		//power-domains = <&pwrdm PDID_T7_DOS_WAVE>;
		ranges;
		io_reg_base {
			reg = <0x0 0xfe310000 0x0 0x10000>;
		};
	};

	vpu: vpu {
		compatible = "amlogic, vpu-s5";
		status = "okay";
		reg =	<0x0 0xfe000000 0x0 0xc00     /* clk */
			 0x0 0xfe00c000 0x0 0xb00     /* pwrctrl */
			 0x0 0xff800000 0x0 0x20000>; /* vcbus */
		clocks = <&clkc CLKID_VAPB_0>,
			<&clkc CLKID_SYS_CLK_VPU_INTR>,
			<&clkc CLKID_VPU0>,
			<&clkc CLKID_VPU1>,
			<&clkc CLKID_VPU>;
		clock-names =	"vapb_clk",
				"vpu_intr_gate",
				"vpu_clk0",
				"vpu_clk1",
				"vpu_clk";
		clk_level = <7>;
		/* 0: 100.0M    1: 166.7M    2: 200.0M    3: 250.0M */
		/* 4: 333.3M    5: 400.0M    6: 500.0M    7: 666.7M */
	};

	meson_uvm{
		compatible = "amlogic, meson_uvm";
		status = "okay";
	};

	meson_videotunnel{
		compatible = "amlogic, meson_videotunnel";
		status = "okay";
	};

	video_composer {
		compatible = "amlogic, video_composer";
		dev_name = "video_composer";
		status = "okay";
	};

	rdma{
		compatible = "amlogic, meson-t3, rdma";
		status = "okay";
		interrupts = <GIC_SPI 102 IRQ_TYPE_EDGE_RISING>;
		interrupt-names = "rdma";
		/* after sc2 */
		reset-names = "rdma";
		resets = <&reset RESET_RDMA>;
		rdma_table_page_count = <16>;
	};

	dsc: dsc {
		compatible = "amlogic, dsc-s5";
		status = "okay";
		reg = <0x0 0xfe0be000 0x0 0x80>;
	};

	vclk_serve: vclk_serve {
		compatible = "amlogic, vclk_serve";
		status = "okay";
		reg = <0x0 0xfe008000 0x0 0x300    /* ana reg */
			0x0 0xfe000000 0x0 0xc00>; /* clk reg */
	};

	vout_mux: vout_mux {
		compatible = "amlogic, vout_mux-s5";
		status = "okay";
		clocks = <&clkc CLKID_FCLK_DIV5>, <&clkc CLKID_VIN_MEAS>;
		clock-names = "fclk_div5", "vdin_meas_clk";
	};

	vout: vout {
		compatible = "amlogic, vout";
		status = "okay";
	};

	dummy_venc: dummy_venc {
		compatible = "amlogic, dummy_venc_s5";
		status = "okay";
	};

	ir: ir@8000 {
		compatible = "amlogic, meson-ir";
		reg = <0x0 0xfe084040 0x0 0x44>,
			<0x0 0xfe084000 0x0 0x20>;
		status = "disable";
		protocol = <REMOTE_TYPE_NEC>;
		interrupts = <GIC_SPI 61 IRQ_TYPE_EDGE_RISING>;
		map = <&custom_maps>;
		max_frame_time = <200>;
	};

	gpu_tsensor: gpu_tsensor@fe094000 {
		compatible = "amlogic, r1p1-tsensor";
		status = "okay";
		reg = <0x0 0xfe094000 0x0 0x50>;
		tsensor_id = <2>;
		cal_type = <0x11>;
		cal_coeff = <324 424 3159 9411>;
		rtemp = <115000>;
		interrupts = <GIC_SPI 72 IRQ_TYPE_LEVEL_HIGH>;
		clocks = <&clkc CLKID_TS_CLK>;
		clock-names = "ts_comp";
		#thermal-sensor-cells = <1>;
		power-domains = <&pwrdm PDID_S5_MALI_TOP>;
		reset-names = "ts_rst";
		resets = <&reset RESET_TS_GPU>;
	};

	a55_tsensor: a55_tsensor@fe022000 {
		compatible = "amlogic, r1p1-tsensor";
		status = "okay";
		reg = <0x0 0xfe022000 0x0 0x50>;
		tsensor_id = <1>;
		cal_type = <0x11>;
		cal_coeff = <324 424 3159 9411>;
		rtemp = <115000>;
		interrupts = <GIC_SPI 30 IRQ_TYPE_LEVEL_HIGH>;
		clocks = <&clkc CLKID_TS_CLK>;
		clock-names = "ts_comp";
		#thermal-sensor-cells = <1>;
		reset-names = "ts_rst";
		resets = <&reset RESET_TS_A55>;
	};

	vpu_tsensor: vpu_tsensor@fe0a2000 {
		compatible = "amlogic, r1p1-tsensor";
		status = "okay";
		reg = <0x0 0xfe0a2000 0x0 0x50>;
		tsensor_id = <3>;
		cal_type = <0x11>;
		cal_coeff = <324 424 3159 9411>;
		rtemp = <115000>;
		interrupts = <GIC_SPI 71 IRQ_TYPE_LEVEL_HIGH>;
		clocks = <&clkc CLKID_TS_CLK>;
		clock-names = "ts_comp";
		#thermal-sensor-cells = <1>;
		reset-names = "ts_rst";
		resets = <&reset RESET_TS_VPU>;
	};

	dos_tsensor: dos_tsensor@fe0a4000 {
		compatible = "amlogic, r1p1-tsensor";
		status = "okay";
		reg = <0x0 0xfe0a4000 0x0 0x50>;
		tsensor_id = <4>;
		cal_type = <0x11>;
		cal_coeff = <324 424 3159 9411>;
		rtemp = <115000>;
		interrupts = <GIC_SPI 70 IRQ_TYPE_LEVEL_HIGH>;
		clocks = <&clkc CLKID_TS_CLK>;
		clock-names = "ts_comp";
		#thermal-sensor-cells = <1>;
		power-domains = <&pwrdm PDID_S5_DOS_TOP_WRAP>;
		reset-names = "ts_rst";
		resets = <&reset RESET_TS_DOS>;
	};

	nna_tsensor: nna_tsensor@fe096000 {
		compatible = "amlogic, r1p1-tsensor";
		status = "okay";
		reg = <0x0 0xfe096000 0x0 0x50>;
		tsensor_id = <5>;
		cal_type = <0x11>;
		cal_coeff = <324 424 3159 9411>;
		rtemp = <115000>;
		interrupts = <GIC_SPI 154 IRQ_TYPE_LEVEL_HIGH>;
		clocks = <&clkc CLKID_TS_CLK>;
		clock-names = "ts_comp";
		#thermal-sensor-cells = <1>;
		power-domains = <&pwrdm PDID_S5_NNA_4T>;
		reset-names = "ts_rst";
		resets = <&reset RESET_TS_NNA>;
	};

	meson_cooldev: meson-cooldev@0 {
		status = "okay";
		compatible = "amlogic, meson-cooldev";
		cooling_devices {
			cpucore_cool_cluster0 {
				cluster_id = <0>;
				node_name = "cpucore_cool0";
				device_type = "cpucore";
			};
			cpucore_cool_cluster1 {
				cluster_id = <1>;
				node_name = "cpucore_cool1";
				device_type = "cpucore";
			};
			gpufreq_cool {
				dyn_coeff = <358>;
				node_name = "valhall";
				device_type = "gpufreq";
			};
			gpucore_cool {
				node_name = "gpucore_cooldev";
				device_type = "gpucore";
			};
		};
		cpucore_cool0:cpucore_cool0 {
			#cooling-cells = <2>;
		};
		cpucore_cool1:cpucore_cool1 {
			#cooling-cells = <2>;
		};
		gpucore_cooldev:gpucore_cooldev {
			#cooling-cells = <2>;
		};
	};/*meson cooling devices end*/

	thermal-zones {
		gpu_thermal: gpu_thermal {
			status = "okay";
			polling-delay = <2000>;
			polling-delay-passive = <500>;
			sustainable-power = <5160>;
			thermal-sensors = <&gpu_tsensor 1>;
			trips {
				gpuswitch_on: trip-point@0 {
					temperature = <80000>;
					hysteresis = <5000>;
					type = "passive";
				};
				gpucontrol: trip-point@1 {
					temperature = <90000>;
					hysteresis = <5000>;
					type = "passive";
				};
				gpuhot: trip-point@2 {
					temperature = <100000>;
					hysteresis = <5000>;
					type = "hot";
				};
				gpucritical: trip-point@3 {
					temperature = <110000>;
					hysteresis = <1000>;
					type = "critical";
				};
			};
			cooling-maps {
				gpufreq_cooling_map {
					trip = <&gpucontrol>;
					cooling-device = <&gpu 0 3>;
					contribution = <1024>;
				};
				gpucore_cooling_map {
					trip = <&gpuhot>;
					cooling-device = <&gpucore_cooldev 0 1>;
					contribution = <1024>;
				};
			};
		};
		soc_thermal: soc_thermal {
			status = "okay";
			polling-delay = <2000>;
			polling-delay-passive = <1000>;
			sustainable-power = <960>;
			thermal-sensors = <&a55_tsensor 0>;
			trips {
				a55switch_on: trip-point@0 {
					temperature = <80000>;
					hysteresis = <5000>;
					type = "passive";
				};
				a55control: trip-point@1 {
					temperature = <90000>;
					hysteresis = <5000>;
					type = "passive";
				};
				a55hot: trip-point@2 {
					temperature = <100000>;
					hysteresis = <5000>;
					type = "hot";
				};
				a55critical: trip-point@3 {
					temperature = <110000>;
					hysteresis = <1000>;
					type = "critical";
				};
			};
			cooling-maps {
				cpucore_cooling_map {
					trip = <&a55hot>;
					cooling-device = <&cpucore_cool0 0 2>;
					contribution = <1024>;
				};
				cpufreq_cooling_map1 {
					trip = <&a55control>;
					cooling-device = <&CPU0 0 8>;
					contribution = <1024>;
				};
				cpufreq_cooling_map2 {
					trip = <&a55control>;
					cooling-device = <&CPU4 0 8>;
					contribution = <1024>;
				};
			};
		};
		vpu_thermal: vpu_thermal {
			status = "okay";
			polling-delay = <2000>;
			polling-delay-passive = <1000>;
			sustainable-power = <400>;
			thermal-sensors = <&vpu_tsensor 2>;
			trips {
				vpuswitch_on: trip-point@0 {
					temperature = <80000>;
					hysteresis = <5000>;
					type = "passive";
				};
				vpucontrol: trip-point@1 {
					temperature = <90000>;
					hysteresis = <5000>;
					type = "passive";
				};
				vpucritical: trip-point@2 {
					temperature = <110000>;
					hysteresis = <1000>;
					type = "critical";
				};
			};
		};
		dos_thermal: dos_thermal {
			status = "okay";
			polling-delay = <2000>;
			polling-delay-passive = <1000>;
			sustainable-power = <400>;
			thermal-sensors = <&dos_tsensor 3>;
			trips {
				dosswitch_on: trip-point@0 {
					temperature = <80000>;
					hysteresis = <5000>;
					type = "passive";
				};
				doscontrol: trip-point@1 {
					temperature = <90000>;
					hysteresis = <5000>;
					type = "passive";
				};
				doscritical: trip-point@2 {
					temperature = <110000>;
					hysteresis = <1000>;
					type = "critical";
				};
			};
		};
		nna_thermal: nna_thermal {
			status = "okay";
			polling-delay = <2000>;
			polling-delay-passive = <1000>;
			sustainable-power = <3550>;
			thermal-sensors = <&nna_tsensor 4>;
			trips {
				nnaswitch_on: trip-point@0 {
					temperature = <80000>;
					hysteresis = <5000>;
					type = "passive";
				};
				nnacontrol: trip-point@1 {
					temperature = <90000>;
					hysteresis = <5000>;
					type = "passive";
				};
				nnacritical: trip-point@2 {
					temperature = <110000>;
					hysteresis = <1000>;
					type = "critical";
				};
			};
		};
	};/*thermal zone end*/

	ion_dev {
		compatible = "amlogic, ion_dev";
		memory-region = <&ion_cma_reserved
				 &ion_fb_reserved
				 &ion_secure_reserved>;
		status = "okay";
	};

	fb: fb {
		compatible = "amlogic, fb-s5";
		memory-region = <&logo_reserved>;
		status = "disabled";
		interrupts = <GIC_SPI 115 IRQ_TYPE_EDGE_RISING
			GIC_SPI 102 IRQ_TYPE_EDGE_RISING>;
		interrupt-names = "viu-vsync", "rdma";
		/* uboot logo,fb0/fb1 memory size,if afbcd fb0=0x01851000*/
		display_mode_default = "1080p60hz";
		scale_mode = <1>;
		/** 0:VPU free scale 1:OSD free scale 2:OSD super scale */
		display_size_default = <1920 1080 1920 2160 32>;
		/*1920*1080*4*3 = 0x17BB000*/
	};

	irblaster: meson-irblaster@fe08410c {
		compatible = "amlogic, meson_irblaster";
		status = "disabled";
		reg = <0x0 0xfe08410c 0x0 0x10>;
		#irblaster-cells = <2>;
		interrupts = <GIC_SPI 23 IRQ_TYPE_EDGE_RISING>;
	};

	/*if you want to use vdin just modify status to "ok"*/
	vdin0: vdin0 {/*common define*/
		compatible = "amlogic, vdin-s5";
		dev_name = "vdin0";
		status = "disabled";
		/*memory-region = <&vdin0_cma_reserved>;*/
		reserve-iomap = "true";
		flag_cma = <0x101>;/*1:share with codec_mm;2:cma alone*/
		/*MByte, if 10bit disable: 64M(YUV422),
		 *if 10bit enable: 64*1.5 = 96M(YUV422)
		 *if support 4K2K-YUV444-10bit-WR:3840*2160*4*4 ~= 128M
		 *if support 4K2K-YUV422-10bit-wr:3840*2160*3*4 ~= 96M
		 *if support 4K2K-YUV422-8BIT-WR:3840*2160*2*4 ~= 64M
		 *if support 1080p-YUV422-8BIT-WR:1920*1080*2*4 ~= 16M
		 * onebuffer:
		 * worst case:(4096*2160*3 + 2M(afbce issue)) = 27.5M
		 * dw:960x540x3 = 1.5M
		 * total size:(27.5+1.5)x buffernumber
		 */
		/*cma_size = <174>;*/
		/*frame_buff_num = <6>;*/
		interrupts = <0 210 1 /* vdin0 vsync */
				0 214 1 /* vdin1 write down*/
				/*0 206 1*/ /* vpu crash */
				/*0 213 1*/>; /* vdin0 write down*/
		interrupt-names = "vsync_int",
				"mif2_meta_wr_done_int"
				/*"vpu_crash_int",*/
				/*"write_done_int"*/;
		rdma-irq = <2>;
//		clocks = <&clkc CLKID_FCLK_DIV5>, <&clkc CLKID_VDIN_MEAS_GATE>;
//		clock-names = "fclk_div5", "cts_vdin_meas_clk";
		vdin_id = <0>;
		/*vdin write mem color depth support:
		 * bit0:support 8bit
		 * bit1:support 9bit
		 * bit2:support 10bit
		 * bit3:support 12bit
		 * bit4:support yuv422 10bit full pack mode (from txl new add)
		 * bit8:use 8bit  at 4k_50/60hz_10bit
		 * bit9:use 10bit at 4k_50/60hz_10bit
		 * bit10: support 10bit when double write
		 */
		tv_bit_mode = <0x215>;
		/* afbce_bit_mode: (amlogic frame buff compression encoder)
		 * bit0 -- enable afbce
		 * bit1 -- enable afbce compression-lossy
		 * bit4 -- afbce for 4k
		 * bit5 -- afbce for 1080p
		 * bit6 -- afbce for 720p
		 * bit7 -- afbce for smaller resolution
		 */
		afbce_bit_mode = <0x31>;
		/* urgent_en; */
		double_write_en;
		/* vdin v4l2 */
		v4l_support_en = <0>;
		v4l_vd_num = <70>;
		/* v4l2 capability */
		driver   = "vdinvideo";
		card     = "mesonp1";
		bus_info = "vdin0 v4l2";
		version  = <0x20220120>;
		/* fe_ports refer to tvin.h */
		fe_ports = <0x00001001   /* CVBS1 */
			0x00004000   /* HDMI0 */
			0x00004001   /* HDMI1 */
			0x00004002>; /* HDMI2 */
		/* vdin v4l2 end */
	};

	vdin1: vdin1 {/*common define*/
		compatible = "amlogic, vdin-s5";
		dev_name = "vdin1";
		status = "disabled";
		reserve-iomap = "true";
		/*memory-region = <&vdin1_cma_reserved>;*/
		flag_cma = <0>;/*1:share with codec_mm;0:cma alone*/
		interrupts = <0 117 1>,<0 120 1>;
		interrupt-names = "vsync_int","write_done_int";
		rdma-irq = <4>;
//		clocks = <&clock CLK_FPLL_DIV5>,
//			<&clock CLK_VDIN_MEAS_CLK>;
//		clock-names = "fclk_div5", "cts_vdin_meas_clk";

		vdin_id = <1>;
		tv_bit_mode = <0x15>;
		/* vdin v4l2 */
		v4l_support_en = <0>;
		v4l_vd_num = <71>;
		/* v4l2 capability */
		driver   = "vdinvideo";
		card     = "mesonp1";
		bus_info = "vdin1 v4l2";
		version  = <0x20220120>;
		/* fe_ports refer to tvin.h */
		fe_ports = <0x0000a002   /* WB0_VD1 */
			0x0000a003   /* WB0_VD2 */
			0x0000a004   /* WB0_OSD1 */
			0x0000a005   /* WB0_OSD2 */
			0x0000a006   /* WB0_VPP */
			0x0000a007   /* WB0_VDIN_BIST */
			0x0000a008>; /* WB0_POST_BLEND */
		/* vdin v4l2 end */
	};

	amlvecm: amlvecm {
		compatible = "amlogic, vecm-s5";
		status = "disable";
		dev_name = "aml_vecm";
		/*status = "okay";*/
		/*gamma_en = <1>;*/ /*1:enable ;0:disable*/
		/*wb_en = <1>;*/ /*1:enable ;0:disable*/
		/*cm_en = <1>;*/ /*1:enable ;0:disable*/
		/*wb_sel = <0>;*/ /*1:mtx ;0:gainoff*/
		/*vlock_en = <1>;*/ /*1:enable;0:disable*/
		/*vlock_mode = <0x8>;*/
		/* vlock work mode:
		 *bit0:auto ENC
		 *bit1:auto PLL
		 *bit2:manual PLL
		 *bit3:manual ENC
		 *bit4:manual soft ENC
		 *bit5:manual MIX PLL ENC
		 */
		/* vlock_pll_m_limit = <1>;*/
		/* vlock_line_limit = <2>;*/
//		clocks = <&clkc CLKID_VID_LOCK>;
//		clock-names = "cts_vid_lock_clk";
	};

	meson-amvideom {
		compatible = "amlogic, amvideom-s5";
		dev_name = "amvideom";
		status = "okay";
		interrupts = <GIC_SPI 115 IRQ_TYPE_EDGE_RISING
			GIC_SPI 279 IRQ_TYPE_EDGE_RISING>;
		interrupt-names = "vsync", "frame_done";
	};

	vpu_security {
		compatible = "amlogic, meson-s5, vpu_security";
		dev_name = "amlogic-vpu-security";
		status = "okay";
		interrupts = <GIC_SPI 124 IRQ_TYPE_EDGE_RISING>;
		interrupt-names = "vpu_security";
	};

	dmx_aucpu: aucpu {
		compatible = "amlogic, aucpu";
		dev_name = "aml_aucpu";
		status = "okay";
		interrupts = <0 77 1>;
		interrupt-names = "aucpu_irq";
		#address-cells=<2>;
		#size-cells=<2>;
		ranges;
		io_reg_base{
			reg = <0x0 0xfe09e080 0x0 0x100>;
		};
	};

	ge2d {
		compatible = "amlogic, ge2d-s5";
		status = "okay";
		interrupts = <GIC_SPI 94 IRQ_TYPE_EDGE_RISING>;
		interrupt-names = "ge2d";
		clocks = <&clkc CLKID_VAPB_0>,
			<&clkc CLKID_GE2D>;
		clock-names = "clk_vapb_0",
			"clk_ge2d_gate";
		reg = <0x0 0xff840000 0x0 0x2000>;
		power-domains = <&pwrdm PDID_S5_GE2D>;
	};

	vicp {
		compatible = "amlogic, vicp";
		dev_name = "vicp";
		status = "okay";
		interrupts = <GIC_SPI 329 IRQ_TYPE_EDGE_RISING>,
			<GIC_SPI 330 IRQ_TYPE_EDGE_RISING>,
			<GIC_SPI 331 IRQ_TYPE_EDGE_RISING>;
		interrupt-names = "vicp_err", "vicp_rdma", "vicp_proc";
		clocks = <&clkc CLKID_VAPB_0>,
			<&clkc CLKID_CMPR>;
		clock-names = "clk_vapb_0",
			"clk_vicp_gate";
		reg = <0x0 0xfe03e000 0x0 0xe34>;
		power-domains = <&pwrdm PDID_S5_VICP>;
	};

	aml_bt: aml_bt {
		compatible = "amlogic, aml-bt";
		status = "disabled";
	};

	aml_wifi: aml_wifi {
		compatible = "amlogic, aml-wifi";
		status = "disabled";
		irq_trigger_type = "GPIO_IRQ_LOW";
		dhd_static_buf;
		//pinctrl-0 = <&pwm_e_pins>;
		//pinctrl-names = "default";
		pwm_config = <&wifi_pwm_conf>;
	};

	wifi_pwm_conf:wifi_pwm_conf{
		pwm_channel1_conf {
			pwms = <&pwm_ef 1 30550 0>;
			duty-cycle = <15270>;
			times = <8>;
		};
		pwm_channel2_conf {
			pwms = <&pwm_ef 3 30500 0>;
			duty-cycle = <15250>;
			times = <12>;
		};
	};

	gdc {
		#address-cells=<2>;
		#size-cells=<2>;
		status = "disabled";
		compatible = "amlogic, arm-gdc";
		reg = <0 0xfe08e000 0 0x0000100>;
		interrupts = <GIC_SPI 223 IRQ_TYPE_EDGE_RISING>;
		interrupt-names = "gdc";
//		clocks = <&clkc CLKID_GDCCLK_0>,
//			<&clkc CLKID_GDCCLK>,
//			<&clkc CLKID_GDC_CLK>;
//		clock-names = "mux_gate", "mux_sel", "clk_gate";
//		clk-rate = <800000000>;
//		power-domains = <&pwrdm PDID_T7_GDC>;
	};

	amlgdc {
		#address-cells=<2>;
		#size-cells=<2>;
		status = "disabled";
		compatible = "amlogic, aml-gdc-v2";
		reg = <0 0xfe040000 0 0x000015c>,
			<0 0xfe03e000 0 0x000015c>,
			<0 0xfe03c000 0 0x000015c>;
		interrupts = <GIC_SPI 59 IRQ_TYPE_EDGE_RISING>,
			<GIC_SPI 60 IRQ_TYPE_EDGE_RISING>,
			<GIC_SPI 61 IRQ_TYPE_EDGE_RISING>;
		interrupt-names = "amlgdc", "amlgdc1", "amlgdc2";
//		clocks = <&clkc CLKID_DEWARPA>,
//			<&clkc CLKID_DEWARPB>,
//			<&clkc CLKID_DEWARPC>;
//		clock-names = "clk_gate",
//				"clk_gate1",
//				"clk_gate2";
//		clk-rate = <800000000>;
		//power-domains = <&pwrdm PDID_P1_DEWA>,
		//		<&pwrdm PDID_P1_DEWB>,
		//		<&pwrdm PDID_P1_DEWC>;
	};

	mhu_fifo: mhu@0 {
		status = "okay";
		compatible = "amlogic, meson_mhu_fifo";
		reg = <0x0 0xfe006000 0x0 0x1000>,  /* mhu wr fifo */
		      <0x0 0xfe00719C 0x0 0x80>,   /* mhu set reg */
		      <0x0 0xfe00721C 0x0 0x80>,   /* mhu clr reg */
		      <0x0 0xfe00729C 0x0 0x80>,   /* mhu sts reg */
		      <0x0 0xfe007044 0x0 0xc0>;   /* mhu irqctrl reg */
		interrupts = <0 248 1>;   /* irq top */
		mbox-irqmax = <64>;
		mbox-irqctlr = <2>;
		mbox-irqclr = <1>;
		mbox-nums = <2>;
		mbox-names = "ao_to_ap",
			     "ap_to_ao";
		mboxes = <&mhu_fifo S5_AO2REE>,
			 <&mhu_fifo S5_REE2AO>;
		mbox-id = <0x2 0x3>;
		mbox-wr-rd = <1>;
		#mbox-cells = <1>;
	};

	mbox_user: mbox-user@0 {
		status = "okay";
		compatible = "amlogic, meson-mbox-user";
		mbox-nums = <1>;
		mbox-names = "ree2aocpu";
		mboxes = <&mhu_fifo S5_REE2AO>;
		mbox-dests = <MAILBOX_AOCPU>;
	};

	aml_hwspinlock: hwlock {
		status = "okay";
		compatible = "amlogic, hwspinlock";
		syscon = <&aml_hwspinlock_regs 0 0x4>;
		#hwlock-cells = <1>;
	};

	lut_dma:lut_dma {
		compatible = "amlogic, meson-s5, lut_dma";
		status = "okay";
	};

	state_led:state_led {
		compatible = "amlogic,state-led-aocpu";
		status = "disabled";
	};
	efuse: efuse{
		compatible = "amlogic, efuse";
		read_cmd = <0x82000030>;
		write_cmd = <0x82000031>;
		get_max_cmd = <0x82000033>;
		mem_in_base_cmd = <0x82000020>;
		mem_out_base_cmd = <0x82000021>;
		efuse_pattern_size = <0x600>;
		efuse_obj_cmd_status = <0x1>;
		key = <&efusekey>;
		clock-names = "efuse_clk";
		status = "disabled";
	};

	efusekey:efusekey{
		status = "disabled";
		keynum = <4>;
		key0 = <&key_0>;
		key1 = <&key_1>;
		key2 = <&key_2>;
		key3 = <&key_3>;
		key_0:key_0{
			keyname = "mac";
			offset = <0>;
			size = <6>;
		};
		key_1:key_1{
			keyname = "mac_bt";
			offset = <6>;
			size = <6>;
		};
		key_2:key_2{
			keyname = "mac_wifi";
			offset = <12>;
			size = <6>;
		};
		key_3:key_3{
			keyname = "usid";
			offset = <18>;
			size = <16>;
		};
	};

	mfh: mfh {
		compatible = "amlogic, mfh";
		#address-cells = <2>;
		#size-cells = <2>;
		memory-region = <&mfh_fw_reserved>;
		//power-domains = <&pwrdm PDID_P1_M4A>,
		//		<&pwrdm PDID_P1_M4B>;
		power-domain-names = "m4a-core","m4b-core";
//		clocks = <&clkc CLKID_M4_CLK_0>,
//			 <&clkc CLKID_M4_CLK_1>,
//			 <&clkc CLKID_M4_CLK>,
//			 <&clkc CLKID_M4_PLL>;
//		clock-names = "m4_clk0", "m4_clk1", "m4_clk", "m4_pll";
		mfh-cnt = <2>;
		mfh-addr-offset = <0x40000>;
		mfh-name = "mfha",
			   "mfhb";
	};

	gpu_opp_table: gpu_opp_table {
		compatible = "operating-points-v2";

		opp-285 {
			opp-hz = /bits/ 64 <285714281>;
			opp-microvolt = <1150>;
		};
		opp-400 {
			opp-hz = /bits/ 64 <400000000>;
			opp-microvolt = <1150>;
		};
		opp-500 {
			opp-hz = /bits/ 64 <500000000>;
			opp-microvolt = <1150>;
		};
		opp-666 {
			opp-hz = /bits/ 64 <666666666>;
			opp-microvolt = <1150>;
		};
		opp-830 {
			opp-hz = /bits/ 64 <830000000>;
			opp-microvolt = <1150>;
		};
	};

};

&periphs_pinctrl {
	i2c0_pins1:i2c0_pins1 {
		mux {
			groups = "i2c0_scl_d",
				"i2c0_sda_d";
			function = "i2c0";
			drive-strength-microamp = <3000>;
			bias-disable;
		};
	};
	i2c0_pins2:i2c0_pins2 {
		mux {
			groups = "i2c0_scl_e",
				"i2c0_sda_e";
			function = "i2c0";
			drive-strength-microamp = <3000>;
			bias-disable;
		};
	};
	i2c1_pins1:i2c1_pins1 {
		mux {
			groups = "i2c1_scl_a",
				"i2c1_sda_a";
			function = "i2c1";
			drive-strength-microamp = <3000>;
			bias-disable;
		};
	};
	i2c1_pins2:i2c1_pins2 {
		mux {
			groups = "i2c1_scl_h2",
				"i2c1_sda_h3";
			function = "i2c1";
			drive-strength-microamp = <3000>;
			bias-disable;
		};
	};
	i2c1_pins3:i2c1_pins3 {
		mux {
			groups = "i2c1_scl_h6",
				"i2c1_sda_h7";
			function = "i2c1";
			drive-strength-microamp = <3000>;
			bias-disable;
		};
	};

	i2c2_pins1:i2c2_pins1 {
		mux {
			groups = "i2c2_sda_a",
				"i2c2_scl_a";
			function = "i2c2";
			drive-strength-microamp = <3000>;
			bias-disable;
		};
	};
	i2c2_pins2:i2c2_pins2 {
		mux {
			groups = "i2c2_scl_t",
				"i2c2_sda_t";
			function = "i2c2";
			drive-strength-microamp = <3000>;
			bias-disable;
		};
	};
	i2c2_pins3:i2c2_pins3 {
		mux {
			groups = "i2c2_scl_x",
				"i2c2_sda_x";
			function = "i2c2";
			drive-strength-microamp = <3000>;
			bias-disable;
		};
	};
	i2c3_pins1:i2c3_pins1 {
		mux {
			groups = "i2c3_scl_h",
				"i2c3_sda_h";
			function = "i2c3";
			drive-strength-microamp = <3000>;
			bias-disable;
		};
	};
	i2c3_pins2:i2c3_pins2 {
		mux {
			groups = "i2c3_scl_t",
				"i2c3_sda_t";
			function = "i2c3";
			drive-strength-microamp = <3000>;
			bias-disable;
		};
	};
	i2c4_pins1:i2c4_pins1 {
		mux {
			groups = "i2c4_scl_e",
				"i2c4_sda_e";
			function = "i2c4";
			drive-strength-microamp = <3000>;
			bias-disable;
		};
	};
	i2c4_pins2:i2c4_pins2 {
		mux {
			groups = "i2c4_scl_t",
				"i2c4_sda_t";
			function = "i2c4";
			drive-strength-microamp = <3000>;
			bias-disable;
		};
	};
	i2c5_pins1:i2c5_pins1 {
		mux {
			groups = "i2c5_scl_z",
				"i2c5_sda_z";
			function = "i2c5";
			drive-strength-microamp = <3000>;
			bias-disable;
		};
	};
	i2c5_pins2:i2c5_pins2 {
		mux {
			groups = "i2c5_scl_t",
				"i2c5_sda_t";
			function = "i2c5";
			drive-strength-microamp = <3000>;
			bias-disable;
		};
	};
	i2c5_pins3:i2c5_pins3 {
		mux {
			groups = "i2c5_sda_a",
				"i2c5_scl_a";
			function = "i2c5";
			drive-strength-microamp = <3000>;
			bias-disable;
		};
	};

	a_uart_pins1:a_uart1 {
		mux {
			groups = "uart_a_tx_d",
				"uart_a_rx_d";
			function = "uart_a";
		};
	};

	a_uart_pins2:a_uart2 {
		mux {
			groups = "uart_a_tx_c",
				"uart_a_rx_c";
			function = "uart_a";
		};
	};

	b_uart_pins:b_uart {
		mux {
			groups = "uart_b_tx",
				"uart_b_rx",
				"uart_b_cts",
				"uart_b_rts";
			bias-pull-up;
			output-high;
			function = "uart_b";
		};
	};

	c_uart_pins1:c_uart1 {
		mux {
			groups = "uart_c_tx_a",
				"uart_c_rx_a";
			function = "uart_c";
		};
	};

	c_uart_pins2:c_uart2 {
		mux {
			groups = "uart_c_tx_d",
				"uart_c_rx_d";
			function = "uart_c";
		};
	};

	c_uart_pins3:c_uart3 {
		mux {
			groups = "uart_c_tx_h",
				"uart_c_rx_h",
				"uart_c_cts_h",
				"uart_c_rts_h";
			bias-pull-up;
			output-high;
			function = "uart_c";
		};
	};

	d_uart_pins:d_uart {
		mux {
			groups = "uart_d_tx",
				"uart_d_rx";
			function = "uart_d";
		};
	};

	e_uart_pins:e_uart {
		mux {
			groups = "uart_e_tx",
				"uart_e_rx";
			function = "uart_e";
		};
	};

	f_uart_pins:f_uart {
		mux {
			groups = "uart_f_tx",
				"uart_f_rx";
			function = "uart_f";
		};
	};

	/* sdemmc portB */
	sd_to_ao_uart_clr_pins: sd_to_ao_uart_clr_pins {
		mux {
			groups = "GPIOD_0",
				   "GPIOD_1";
			function = "gpio_periphs";
		};
	};

	sdcard_pins: sdcard_pins {
		mux {
			groups = "sdcard_d0",
				 "sdcard_d1",
				 "sdcard_d2",
				 "sdcard_d3",
				 "sdcard_clk",
				 "sdcard_cmd";
			function = "sdcard";
			bias-pull-up;
			drive-strength-microamp = <4000>;
		};
	};

	ao_to_sd_uart_pins: ao_to_sd_uart_pins {
		mux {
			groups = "uart_a_tx_c",
				"uart_a_rx_c";
			function = "uart_a";
			bias-pull-up;
			input-enable;
		};
	};

	ao_uart_pins: ao_uart_pins {
		mux {
			groups = "uart_a_tx_d",
				"uart_a_rx_d";
			function = "uart_a";
			bias-pull-up;
			input-enable;
		};
	};

	sd_clr_all_pins: sd_clr_all_pins {
		mux {
			groups = "GPIOC_0",
				   "GPIOC_1",
				   "GPIOC_2",
				   "GPIOC_3",
				   "GPIOC_5";
			function = "gpio_periphs";
			output-high;
		};
		mux1 {
			groups = "GPIOC_4";
			function = "gpio_periphs";
			output-low;
		};
	};

	sd_clr_noall_pins: sd_clr_noall_pins {
		mux {
			groups = "GPIOC_0",
				   "GPIOC_1",
				   "GPIOC_4",
				   "GPIOC_5";
			function = "gpio_periphs";
			output-high;
		};
	};

	sd_1bit_pins: sd_1bit_pins {
		mux {
			groups = "sdcard_d0",
				 "sdcard_clk",
				 "sdcard_cmd";
			function = "sdcard";
			bias-pull-up;
			drive-strength-microamp = <4000>;
		};
	};

	sdcard_clk_gate_pins: sdcard_clk_gate_pins {
		mux {
			groups = "GPIOC_4";
			function = "gpio_periphs";
			bias-pull-down;
			drive-strength-microamp = <4000>;
		};
	};

	sd_iso7816_pins:sd_iso7816_pins {
		mux {
			groups = "iso7816_clk_z",
				"iso7816_data_z";
			function = "iso7816";
			input-enable;
			bias-pull-down;
		};
	};

	/* sdio port A */
	sdio_pins: sdio {
		mux {
			groups = "sdio_d0",
				 "sdio_d1",
				 "sdio_d2",
				 "sdio_d3",
				 "sdio_clk",
				 "sdio_cmd";
			function = "sdio";
			//bias-disable;
			bias-pull-up;
			drive-strength-microamp = <4000>;
		};
	};

	sdio_clk_gate_pins: sdio_clk_gate {
		mux {
			groups = "GPIOX_4";
			function = "gpio_periphs";
			bias-pull-down;
			drive-strength-microamp = <4000>;
		};
	};

	hdmitx_hpd: hdmitx_hpd {
		mux {
			groups = "hdmitx_hpd_in";
			function = "hdmitx";
			bias-disable;
		};
	};

	hdmitx_hpd_gpio: hdmitx_hpd_gpio {
		mux {
			groups = "hdmitx_hpd_in";
			function = "gpio_periphs";
			bias-disable;
		};
	};

	hdmitx_ddc: hdmitx_ddc {
		mux {
			groups = "hdmitx_sda",
				"hdmitx_sck";
			function = "hdmitx";
			bias-disable;
			drive-strength-microamp = <3000>;
		};
	};

	hdmirx_a_mux:hdmirx_a_mux {
		mux {
			groups = "hdmirx_a_hpd",
				"hdmirx_a_det",
				"hdmirx_a_sda",
				"hdmirx_a_sck";
			function = "hdmirx_a";
		};
	};

	hdmirx_b_mux:hdmirx_b_mux {
		mux {
			groups = "hdmirx_b_hpd",
				"hdmirx_b_det",
				"hdmirx_b_sda",
				"hdmirx_b_sck";
			function = "hdmirx_b";
		};
	};

	hdmirx_c_mux:hdmirx_c_mux {
		mux {
			groups = "hdmirx_c_hpd",
				"hdmirx_c_det",
				"hdmirx_c_sda",
				"hdmirx_c_sck";
			function = "hdmirx_c";
		};
	};

	cec_a: cec_a {
		mux {
			groups = "cec_a";
			function = "cec_a";
		};
	};

	cec_b: cec_b {
		mux {
			groups = "cec_b_h";
			function = "cec_b";
		};
	};

	jtag_a_pins: jtag_a_pin {
		mux {
			groups = "jtag_a_tdi",
				 "jtag_a_tdo",
				 "jtag_a_clk",
				 "jtag_a_tms";
			function = "jtag_a";
		};
	};

	jtag_b_pins: jtag_b_pin {
		mux {
			groups = "jtag_b_tdi",
				 "jtag_b_tdo",
				 "jtag_b_clk",
				 "jtag_b_tms";
			function = "jtag_b";
		};
	};

	pwm_a_pins1: pwm_a_pins1 {
		mux {
			groups = "pwm_a_e";
			function = "pwm_a";
			drive-strength-microamp = <3000>;
		};
	};

	pwm_a_pins2: pwm_a_pins2 {
		mux {
			groups = "pwm_a_x";
			function = "pwm_a";
			drive-strength-microamp = <3000>;
		};
	};

	pwm_b_pins1: pwm_b_pins1 {
		mux {
			groups = "pwm_b_e";
			function = "pwm_b";
			drive-strength-microamp = <3000>;
		};
	};

	pwm_b_pins2: pwm_b_pins2 {
		mux {
			groups = "pwm_b_h";
			function = "pwm_b";
			drive-strength-microamp = <3000>;
		};
	};

	pwm_c_pins1: pwm_c_pins1 {
		mux {
			groups = "pwm_c_e";
			function = "pwm_c";
			drive-strength-microamp = <3000>;
		};
	};

	pwm_c_pins2: pwm_c_pins2 {
		mux {
			groups = "pwm_c_c";
			function = "pwm_c";
			drive-strength-microamp = <3000>;
		};
	};

	pwm_d_pins1: pwm_d_pins1 {
		mux {
			groups = "pwm_d_d";
			function = "pwm_d";
			drive-strength-microamp = <3000>;
		};
	};

	pwm_d_pins2: pwm_d_pins2 {
		mux {
			groups = "pwm_d_e";
			function = "pwm_d";
			drive-strength-microamp = <3000>;
		};
	};

	pwm_e_pins: pwm_e_pins {
		mux {
			groups = "pwm_e";
			function = "pwm_e";
			drive-strength-microamp = <3000>;
		};
	};

	pwm_f_pins: pwm_f_pins {
		mux {
			groups = "pwm_f";
			function = "pwm_f";
			drive-strength-microamp = <3000>;
		};
	};

	pwm_g_pins1: pwm_g_pins1 {
		mux {
			groups = "pwm_g_d";
			function = "pwm_g";
			drive-strength-microamp = <3000>;
		};
	};

	pwm_g_pins2: pwm_g_pins2 {
		mux {
			groups = "pwm_g_x";
			function = "pwm_g";
			drive-strength-microamp = <3000>;
		};
	};

	pwm_h_pins1: pwm_h_pins1 {
		mux {
			groups = "pwm_h_d";
			function = "pwm_h";
			drive-strength-microamp = <3000>;
		};
	};

	pwm_h_pins2: pwm_h_pins2 {
		mux {
			groups = "pwm_h_t";
			function = "pwm_h";
			drive-strength-microamp = <3000>;
		};
	};

	pwm_i_pins1: pwm_i_pins1 {
		mux {
			groups = "pwm_i_d";
			function = "pwm_i";
			drive-strength-microamp = <3000>;
		};
	};

	pwm_i_pins2: pwm_i_pins2 {
		mux {
			groups = "pwm_i_t";
			function = "pwm_i";
			drive-strength-microamp = <3000>;
		};
	};

	pwm_j_pins1: pwm_j_pins1 {
		mux {
			groups = "pwm_j_d";
			function = "pwm_j";
			drive-strength-microamp = <3000>;
		};
	};

	pwm_j_pins2: pwm_j_pins2 {
		mux {
			groups = "pwm_j_t";
			function = "pwm_j";
			drive-strength-microamp = <3000>;
		};
	};

	remote_pins: remote_pin {
		mux {
			groups = "remote_in_d";
			function = "remote_in";
			bias-disable;
		};
	};

	spicc0_pins_c: spicc0_pins_c {
		mux {
			groups = "spi_a_mosi_c",
				 "spi_a_miso_c",
				 "spi_a_clk_c";
			function = "spi_a";
			drive-strength-microamp = <2000>;
		};
	};

	spicc0_cs_pins_c: spicc0_cs_pins_c {
		mux {
			groups = "spi_a_ss0_c"; //GPIOC_2
			function = "spi_a";
			drive-strength-microamp = <2000>;
		};
	};

	spicc0_pins_t: spicc0_pins_t {
		mux {
			groups = "spi_a_mosi_t",
				 "spi_a_miso_t",
				 "spi_a_sclk_t";
			function = "spi_a";
			drive-strength-microamp = <2000>;
		};
	};

	spicc0_cs_pins_t: spicc0_cs_pins_t {
		mux {
			groups = "spi_a_ss0_t"; //GPIOT_4
			function = "spi_a";
			drive-strength-microamp = <2000>;
		};
	};

	spicc1_pins: spicc1_pins {
		mux {
			groups = "spi_b_mosi",
				 "spi_b_miso",
				 "spi_b_sclk";
			function = "spi_b";
			drive-strength-microamp = <2000>;
		};
	};

	spicc1_cs_pins: spicc1_cs_pins {
		mux {
			groups = "spi_b_ss0"; //GPIOH_6
			function = "spi_b";
			drive-strength-microamp = <2000>;
		};
	};

	spicc2_pins_a: spicc2_pins_a {
		mux {
			groups = "spi_c_mosi_a",
				 "spi_c_miso_a",
				 "spi_c_sclk_a";
			function = "spi_c";
			drive-strength-microamp = <2000>;
		};
	};

	spicc2_cs_pins_a: spicc2_cs_pins_a {
		mux {
			groups = "spi_c_ss0_a"; //GPIOA_2
			function = "spi_c";
			drive-strength-microamp = <2000>;
		};
	};

	spicc2_pins_x: spicc2_pins_x {
		mux {
			groups = "spi_c_mosi_x",
				 "spi_c_miso_x",
				 "spi_c_clk_x";
			function = "spi_c";
			drive-strength-microamp = <2000>;
		};
	};

	spicc2_cs_pins_x: spicc2_cs_pins_x {
		mux {
			groups = "spi_c_ss0_x"; //GPIOX_2
			function = "spi_c";
			drive-strength-microamp = <2000>;
		};
	};

	irblaster_pins1:irblaster_pin1 {
		mux {
			groups = "remote_out_d4";
			function = "remote_out";
		};
	};

	irblaster_pins2:irblaster_pin2 {
		mux {
			groups = "remote_out_d6";
			function = "remote_out";
		};
	};

	spdifout_d: spdifout_d {
		mux { /* GPIOD_8 */
			groups = "spdif_out_d";
			function = "spdif_out";
		};
	};

	spdifout_d_mute: spdifout_d_mute {
		mux { /* GPIOD_8 */
			groups = "GPIOD_8";
			function = "gpio_periphs";
			output-low;
		};
	};

	spdifout_t: spdifout_t {
		mux { /* GPIOT_3 */
			groups = "spdif_out_t";
			function = "spdif_out";
		};
	};

	spdifout_t_mute: spdifout_t_mute {
		mux { /* GPIOT_3 */
			groups = "GPIOT_3";
			function = "gpio_periphs";
			output-low;
		};
	};

	spdifin_d: spdifin_d {
		mux {/* GPIOD_9 */
			groups = "spdif_in_d";
			function = "spdif_in";
		};
	};

	spdifin_t: spdifin_t {
		mux {/* GPIOT_4 */
			groups = "spdif_in_t";
			function = "spdif_in";
		};
	};
	mclk_0_pins: mclk_0_pin {
		mux { /* GPIOT_14 */
			groups = "mclk_0";
			function = "mclk";
		};
	};
	mclk_1_pins: mclk_1_pin {
		mux { /* GPIOT_19 */
			groups = "mclk_1";
			function = "mclk";
		};
	};

	mclk_2_pins: mclk_2_pin {
		mux { /* GPIOT_K8 */
			groups = "mclk_2";
			function = "mclk";
		};
	};

	mclk_3_pins: mclk_3_pin {
		mux { /* GPIOT_W0 */
			groups = "mclk_3_w";
			function = "mclk";
		};
	};
	lcd_vbyone_a_pins: lcd_vbyone_a_pin {
		mux {
			groups = "vx1_a_htpdn","vx1_a_lockn";
			function = "vx1_a";
		};
	};

	lcd_vbyone_b_pins: lcd_vbyone_b_pin {
		mux {
			groups = "vx1_b_htpdn","vx1_b_lockn";
			function = "vx1_b";
		};
	};

	lcd_edp_a_pins: lcd_edp_a_pin {
		mux {
			groups = "edp_a_hpd";
			function = "edp_a";
		};
	};

	lcd_edp_b_pins: lcd_edp_b_pin {
		mux {
			groups = "edp_b_hpd";
			function = "edp_b";
		};
	};

	eth_pins: eth {
		mux {
			groups = "eth_mdio",
				 "eth_mdc",
				 "eth_rgmii_rx_clk",
				 "eth_rx_dv",
				 "eth_rxd0",
				 "eth_rxd1",
				 "eth_txen",
				 "eth_txd0",
				 "eth_txd1";
			function = "eth";
			drive-strength-microamp = <4000>;
			bias-disable;
		};
	};

	eth_rgmii_pins: eth-rgmii {
		mux {
			groups = "eth_rxd2_rgmii",
				 "eth_rxd3_rgmii",
				 "eth_rgmii_tx_clk",
				 "eth_txd2_rgmii",
				 "eth_txd3_rgmii";
			function = "eth";
			drive-strength-microamp = <4000>;
			bias-disable;
		};
	};

	pcieck_0_pins: pcieck_0_pin {
		mux {
			/* GPIOT_23 */
			groups = "pcieck_b_reqn";
			function = "pcieck";
		};
	};

	pcieck_1_pins: pcieck_1_pin {
		mux {
			/* GPIOX_19 */
			groups = "pcieck_c_reqn";
			function = "pcieck";
		};
	};
};

&storage_pinctrl {
	emmc_pins: emmc {
		mux-0 {
			groups = "emmc_nand_d0",
				 "emmc_nand_d1",
				 "emmc_nand_d2",
				 "emmc_nand_d3",
				 "emmc_nand_d4",
				 "emmc_nand_d5",
				 "emmc_nand_d6",
				 "emmc_nand_d7",
				 "emmc_cmd";
			function = "emmc";
			bias-pull-up;
			drive-strength-microamp = <4000>;
		};

		mux-1 {
			groups = "emmc_clk";
			function = "emmc";
			bias-disable;
			drive-strength-microamp = <4000>;
		};
	};

	emmc_ds_pins: emmc-ds {
		mux {
			groups = "emmc_nand_ds";
			function = "emmc";
			bias-pull-down;
			drive-strength-microamp = <4000>;
		};
	};

	emmc_clk_gate_pins: emmc_clk_gate {
		mux {
			groups = "GPIOB_8";
			function = "gpio_storage";
			bias-pull-down;
			drive-strength-microamp = <4000>;
		};
	};

	spifc_all_pins: spifc_all_pins {
		mux {
			groups =  "spif_hold",
				"spif_mo",
				"spif_mi",
				"spif_clk",
				"spif_wp",
				"spif_cs";
			function = "spif";
			drive-strength-microamp = <3000>;
		};
	};
};

&gpu{
	status = "okay";
	operating-points-v2 = <&gpu_opp_table>;
	reg =   <0 0xFE400000 0 0x04000>, /*mali APB bus base address*/
		<0 0xFE002000 0 0x01000>; /*reset register*/

	interrupts = <GIC_SPI 272 IRQ_TYPE_LEVEL_HIGH>,
		     <GIC_SPI 273 IRQ_TYPE_LEVEL_HIGH>,
		     <GIC_SPI 271 IRQ_TYPE_LEVEL_HIGH>;
	interrupt-names = "GPU", "MMU", "JOB";
	power-domains = <&pwrdm PDID_S5_MALI_TOP>;
	num_of_pp = <2>;
	system-coherency = <31>;
	clocks = <&clkc CLKID_MALI>;
	clock-names = "gpu_mux";

	/*
	 * Mali clocking is provided by two identical clock paths
	 * MALI_0 and MALI_1 muxed to a single clock by a glitch
	 * free mux to safely change frequency while running.
	 */
	assigned-clocks = <&clkc CLKID_MALI0_SEL>,
			  <&clkc CLKID_MALI0>,
			  <&clkc CLKID_MALI>; /* Glitch free mux */
	assigned-clock-parents = <&clkc CLKID_SYS2_PLL>,
				 <0>, /* Do Nothing */
				 <&clkc CLKID_MALI0>;
	assigned-clock-rates = <0>, /* Do Nothing */
			       <800000000>,
			       <0>; /* Do Nothing */

	tbl =  <&dvfs250_cfg
		&dvfs400_cfg
		&dvfs500_cfg
		&dvfs666_cfg
		&dvfs830_cfg
		&dvfs830_cfg>;

//	reset_cfg:reset_cfg {
//		reg_level = <0x16>;
//		reg_mask = <0x26>;
//		reg_bit = <10>;
//	};

};

